AUTOSAR XML (schema 4-2-2)
package /STELLANTIS/EPT/ASWCs
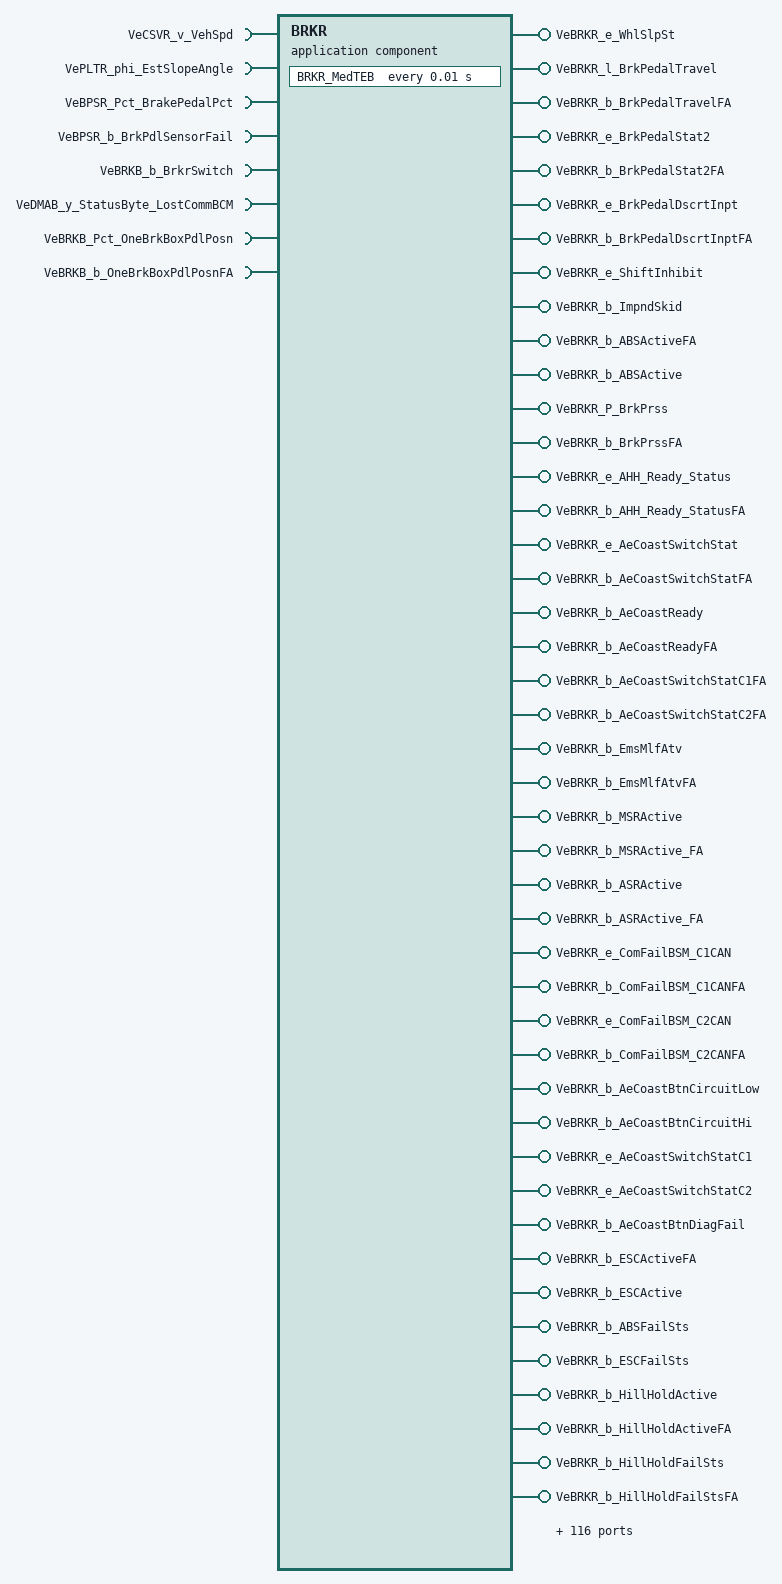
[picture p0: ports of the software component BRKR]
  application sw component type BRKR
    8 x require port, all with nonqueued-receiver-com-spec{data-element=Value, init-value=0}:
      VeCSVR_v_VehSpd: required-interface=VeCSVR_v_VehSpd
      VePLTR_phi_EstSlopeAngle: required-interface=VePLTR_phi_EstSlopeAngle
      VeBPSR_Pct_BrakePedalPct: required-interface=VeBPSR_Pct_BrakePedalPct
      VeBPSR_b_BrkPdlSensorFail: required-interface=VeBPSR_b_BrkPdlSensorFail
      VeBRKB_b_BrkrSwitch: required-interface=VeBRKB_b_BrkrSwitch
      VeDMAB_y_StatusByte_LostCommBCM: required-interface=VeDMAB_y_StatusByte_LostCommBCM
      VeBRKB_Pct_OneBrkBoxPdlPosn: required-interface=VeBRKB_Pct_OneBrkBoxPdlPosn
      VeBRKB_b_OneBrkBoxPdlPosnFA: required-interface=VeBRKB_b_OneBrkBoxPdlPosnFA
    160 x provide port:
      VeBRKR_e_WhlSlpSt: nonqueued-sender-com-spec{data-element=Value, init-value=CeBRKR_e_NoWhlSlpDetected}, provided-interface=VeBRKR_e_WhlSlpSt
      VeBRKR_l_BrkPedalTravel: nonqueued-sender-com-spec{data-element=Value, init-value=0}, provided-interface=VeBRKR_l_BrkPedalTravel
      VeBRKR_b_BrkPedalTravelFA: nonqueued-sender-com-spec{data-element=Value, init-value=0}, provided-interface=VeBRKR_b_BrkPedalTravelFA
      VeBRKR_e_BrkPedalStat2: nonqueued-sender-com-spec{data-element=Value, init-value=CeBRKR_e_BrkNotApplied}, provided-interface=VeBRKR_e_BrkPedalStat2
      VeBRKR_b_BrkPedalStat2FA: nonqueued-sender-com-spec{data-element=Value, init-value=0}, provided-interface=VeBRKR_b_BrkPedalStat2FA
      VeBRKR_e_BrkPedalDscrtInpt: nonqueued-sender-com-spec{data-element=Value, init-value=CeBRKR_e_BrkNotApplied}, provided-interface=VeBRKR_e_BrkPedalDscrtInpt
      VeBRKR_b_BrkPedalDscrtInptFA: nonqueued-sender-com-spec{data-element=Value, init-value=0}, provided-interface=VeBRKR_b_BrkPedalDscrtInptFA
      VeBRKR_e_ShiftInhibit: nonqueued-sender-com-spec{data-element=Value, init-value=CeBRKR_e_NoAction}, provided-interface=VeBRKR_e_ShiftInhibit
      VeBRKR_b_ImpndSkid: nonqueued-sender-com-spec{data-element=Value, init-value=0}, provided-interface=VeBRKR_b_ImpndSkid
      VeBRKR_b_ABSActiveFA: nonqueued-sender-com-spec{data-element=Value, init-value=0}, provided-interface=VeBRKR_b_ABSActiveFA
      VeBRKR_b_ABSActive: nonqueued-sender-com-spec{data-element=Value, init-value=0}, provided-interface=VeBRKR_b_ABSActive
      VeBRKR_P_BrkPrss: nonqueued-sender-com-spec{data-element=Value, init-value=0}, provided-interface=VeBRKR_P_BrkPrss
      VeBRKR_b_BrkPrssFA: nonqueued-sender-com-spec{data-element=Value, init-value=0}, provided-interface=VeBRKR_b_BrkPrssFA
      VeBRKR_e_AHH_Ready_Status: nonqueued-sender-com-spec{data-element=Value, init-value=CeBRKR_e_AHH_NotReady}, provided-interface=VeBRKR_e_AHH_Ready_Status
      VeBRKR_b_AHH_Ready_StatusFA: nonqueued-sender-com-spec{data-element=Value, init-value=0}, provided-interface=VeBRKR_b_AHH_Ready_StatusFA
      VeBRKR_e_AeCoastSwitchStat: nonqueued-sender-com-spec{data-element=Value, init-value=CeBRKR_e_Button_Unpressed}, provided-interface=VeBRKR_e_AeCoastSwitchStat
      VeBRKR_b_AeCoastSwitchStatFA: nonqueued-sender-com-spec{data-element=Value, init-value=0}, provided-interface=VeBRKR_b_AeCoastSwitchStatFA
      VeBRKR_b_AeCoastReady: nonqueued-sender-com-spec{data-element=Value, init-value=0}, provided-interface=VeBRKR_b_AeCoastReady
      VeBRKR_b_AeCoastReadyFA: nonqueued-sender-com-spec{data-element=Value, init-value=0}, provided-interface=VeBRKR_b_AeCoastReadyFA
      VeBRKR_b_AeCoastSwitchStatC1FA: nonqueued-sender-com-spec{data-element=Value, init-value=0}, provided-interface=VeBRKR_b_AeCoastSwitchStatC1FA
      VeBRKR_b_AeCoastSwitchStatC2FA: nonqueued-sender-com-spec{data-element=Value, init-value=0}, provided-interface=VeBRKR_b_AeCoastSwitchStatC2FA
      VeBRKR_b_EmsMlfAtv: nonqueued-sender-com-spec{data-element=Value, init-value=0}, provided-interface=VeBRKR_b_EmsMlfAtv
      VeBRKR_b_EmsMlfAtvFA: nonqueued-sender-com-spec{data-element=Value, init-value=0}, provided-interface=VeBRKR_b_EmsMlfAtvFA
      VeBRKR_b_MSRActive: nonqueued-sender-com-spec{data-element=Value, init-value=0}, provided-interface=VeBRKR_b_MSRActive
      VeBRKR_b_MSRActive_FA: nonqueued-sender-com-spec{data-element=Value, init-value=0}, provided-interface=VeBRKR_b_MSRActive_FA
      VeBRKR_b_ASRActive: nonqueued-sender-com-spec{data-element=Value, init-value=0}, provided-interface=VeBRKR_b_ASRActive
      VeBRKR_b_ASRActive_FA: nonqueued-sender-com-spec{data-element=Value, init-value=0}, provided-interface=VeBRKR_b_ASRActive_FA
      VeBRKR_e_ComFailBSM_C1CAN: nonqueued-sender-com-spec{data-element=Value, init-value=CeBRKR_e_NoFaultBSM_C1}, provided-interface=VeBRKR_e_ComFailBSM_C1CAN
      VeBRKR_b_ComFailBSM_C1CANFA: nonqueued-sender-com-spec{data-element=Value, init-value=0}, provided-interface=VeBRKR_b_ComFailBSM_C1CANFA
      VeBRKR_e_ComFailBSM_C2CAN: nonqueued-sender-com-spec{data-element=Value, init-value=CeBRKR_e_NoFaultBSM_C2}, provided-interface=VeBRKR_e_ComFailBSM_C2CAN
      VeBRKR_b_ComFailBSM_C2CANFA: nonqueued-sender-com-spec{data-element=Value, init-value=0}, provided-interface=VeBRKR_b_ComFailBSM_C2CANFA
      VeBRKR_b_AeCoastBtnCircuitLow: nonqueued-sender-com-spec{data-element=Value, init-value=0}, provided-interface=VeBRKR_b_AeCoastBtnCircuitLow
      VeBRKR_b_AeCoastBtnCircuitHi: nonqueued-sender-com-spec{data-element=Value, init-value=0}, provided-interface=VeBRKR_b_AeCoastBtnCircuitHi
      VeBRKR_e_AeCoastSwitchStatC1: nonqueued-sender-com-spec{data-element=Value, init-value=CeBRKR_e_Button_Unpressed}, provided-interface=VeBRKR_e_AeCoastSwitchStatC1
      VeBRKR_e_AeCoastSwitchStatC2: nonqueued-sender-com-spec{data-element=Value, init-value=CeBRKR_e_Button_Unpressed}, provided-interface=VeBRKR_e_AeCoastSwitchStatC2
      VeBRKR_b_AeCoastBtnDiagFail: nonqueued-sender-com-spec{data-element=Value, init-value=0}, provided-interface=VeBRKR_b_AeCoastBtnDiagFail
      VeBRKR_b_ESCActiveFA: nonqueued-sender-com-spec{data-element=Value, init-value=0}, provided-interface=VeBRKR_b_ESCActiveFA
      VeBRKR_b_ESCActive: nonqueued-sender-com-spec{data-element=Value, init-value=0}, provided-interface=VeBRKR_b_ESCActive
      VeBRKR_b_ABSFailSts: nonqueued-sender-com-spec{data-element=Value, init-value=0}, provided-interface=VeBRKR_b_ABSFailSts
      VeBRKR_b_ESCFailSts: nonqueued-sender-com-spec{data-element=Value, init-value=0}, provided-interface=VeBRKR_b_ESCFailSts
      VeBRKR_b_HillHoldActive: nonqueued-sender-com-spec{data-element=Value, init-value=0}, provided-interface=VeBRKR_b_HillHoldActive
      VeBRKR_b_HillHoldActiveFA: nonqueued-sender-com-spec{data-element=Value, init-value=0}, provided-interface=VeBRKR_b_HillHoldActiveFA
      VeBRKR_b_HillHoldFailSts: nonqueued-sender-com-spec{data-element=Value, init-value=0}, provided-interface=VeBRKR_b_HillHoldFailSts
      VeBRKR_b_HillHoldFailStsFA: nonqueued-sender-com-spec{data-element=Value, init-value=0}, provided-interface=VeBRKR_b_HillHoldFailStsFA
      VeBRKR_e_AeCoastSwitch: nonqueued-sender-com-spec{data-element=Value, init-value=CeBRKR_e_Button_Unpressed}, provided-interface=VeBRKR_e_AeCoastSwitch
      VeBRKR_b_AeCoastSwitchFA: nonqueued-sender-com-spec{data-element=Value, init-value=0}, provided-interface=VeBRKR_b_AeCoastSwitchFA
      VeBRKR_e_OPDHoldStatus: nonqueued-sender-com-spec{data-element=Value, init-value=CeBRKR_e_In_Active}, provided-interface=VeBRKR_e_OPDHoldStatus
      VeBRKR_b_OPDHoldStatusFA: nonqueued-sender-com-spec{data-element=Value, init-value=0}, provided-interface=VeBRKR_b_OPDHoldStatusFA
      VeBRKR_b_CMMIntervention: nonqueued-sender-com-spec{data-element=Value, init-value=0}, provided-interface=VeBRKR_b_CMMIntervention
      VeBRKR_b_FunctionSts: nonqueued-sender-com-spec{data-element=Value, init-value=0}, provided-interface=VeBRKR_b_FunctionSts
      VeBRKR_e_BrakeSrc: nonqueued-sender-com-spec{data-element=Value, init-value=CeBRKR_e_BrkPdlDscrtInpt}, provided-interface=VeBRKR_e_BrakeSrc
      VeBRKR_b_BrkMaxTrqIntrvntn: nonqueued-sender-com-spec{data-element=Value, init-value=0}, provided-interface=VeBRKR_b_BrkMaxTrqIntrvntn
      VeBRKR_b_BrkMinTrqIntrvntn: nonqueued-sender-com-spec{data-element=Value, init-value=0}, provided-interface=VeBRKR_b_BrkMinTrqIntrvntn
      VeBRKR_b_BrkMaxTrqIntrvntnFA: nonqueued-sender-com-spec{data-element=Value, init-value=0}, provided-interface=VeBRKR_b_BrkMaxTrqIntrvntnFA
      VeBRKR_b_BrkMinTrqIntrvntnFA: nonqueued-sender-com-spec{data-element=Value, init-value=0}, provided-interface=VeBRKR_b_BrkMinTrqIntrvntnFA
      VeBRKR_b_ReqSSC_IdlDst: nonqueued-sender-com-spec{data-element=Value, init-value=0}, provided-interface=VeBRKR_b_ReqSSC_IdlDst
      VeBRKR_b_ShortToGround: nonqueued-sender-com-spec{data-element=Value, init-value=0}, provided-interface=VeBRKR_b_ShortToGround
      VeBRKR_b_ShortToPower: nonqueued-sender-com-spec{data-element=Value, init-value=0}, provided-interface=VeBRKR_b_ShortToPower
      VeBRKR_b_ShortToOpen: nonqueued-sender-com-spec{data-element=Value, init-value=0}, provided-interface=VeBRKR_b_ShortToOpen
      VeBRKR_b_AeCoastBtnCircuitLowC1: nonqueued-sender-com-spec{data-element=Value, init-value=0}, provided-interface=VeBRKR_b_AeCoastBtnCircuitLowC1
      VeBRKR_b_AeCoastBtnCircuitLowC2: nonqueued-sender-com-spec{data-element=Value, init-value=0}, provided-interface=VeBRKR_b_AeCoastBtnCircuitLowC2
      VeBRKR_b_AeCoastBtnCircuitHiC1: nonqueued-sender-com-spec{data-element=Value, init-value=0}, provided-interface=VeBRKR_b_AeCoastBtnCircuitHiC1
      VeBRKR_b_AeCoastBtnCircuitHiC2: nonqueued-sender-com-spec{data-element=Value, init-value=0}, provided-interface=VeBRKR_b_AeCoastBtnCircuitHiC2
      VeBRKR_e_ExtBrkReqOff: nonqueued-sender-com-spec{data-element=Value, init-value=CeBRKR_e_NoReq}, provided-interface=VeBRKR_e_ExtBrkReqOff
      VeBRKR_b_ExtBrkReqOffFA: nonqueued-sender-com-spec{data-element=Value, init-value=0}, provided-interface=VeBRKR_b_ExtBrkReqOffFA
      VeBRKR_b_BrkPdlFlt: nonqueued-sender-com-spec{data-element=Value, init-value=0}, provided-interface=VeBRKR_b_BrkPdlFlt
      VeBRKR_b_BrkPdlFltFA: nonqueued-sender-com-spec{data-element=Value, init-value=0}, provided-interface=VeBRKR_b_BrkPdlFltFA
      VeBRKR_e_ExtTcsReqOff: nonqueued-sender-com-spec{data-element=Value, init-value=CeBRKR_e_NoReq}, provided-interface=VeBRKR_e_ExtTcsReqOff
      VeBRKR_Pct_BrkTravelSts: nonqueued-sender-com-spec{data-element=Value, init-value=0}, provided-interface=VeBRKR_Pct_BrkTravelSts
      VeBRKR_b_BrkTravelStsFA: nonqueued-sender-com-spec{data-element=Value, init-value=0}, provided-interface=VeBRKR_b_BrkTravelStsFA
      VeBRKR_b_ESCFailStsFA: nonqueued-sender-com-spec{data-element=Value, init-value=0}, provided-interface=VeBRKR_b_ESCFailStsFA
      VeBRKR_pbar_BrakePedalPressure: nonqueued-sender-com-spec{data-element=Value, init-value=0}, provided-interface=VeBRKR_pbar_BrakePedalPressure
      VeBRKR_b_ESCIntervention: nonqueued-sender-com-spec{data-element=Value, init-value=0}, provided-interface=VeBRKR_b_ESCIntervention
      VeBRKR_e_FaultSts_RgnCntrlSwCktHi: nonqueued-sender-com-spec{data-element=Value, init-value=CeDFIB_e_Init}, provided-interface=VeBRKR_e_FaultSts_RgnCntrlSwCktHi
      VeBRKR_e_FaultSts_RgnCntrlSwCktLo: nonqueued-sender-com-spec{data-element=Value, init-value=CeDFIB_e_Init}, provided-interface=VeBRKR_e_FaultSts_RgnCntrlSwCktLo
      VeBRKR_e_FaultSts_RgnCntrlSwCkt: nonqueued-sender-com-spec{data-element=Value, init-value=CeDFIB_e_Init}, provided-interface=VeBRKR_e_FaultSts_RgnCntrlSwCkt
      VeBRKR_b_VehicleStandStillSts: nonqueued-sender-com-spec{data-element=Value, init-value=0}, provided-interface=VeBRKR_b_VehicleStandStillSts
      VeBRKR_b_VehicleStandStillStsFA: nonqueued-sender-com-spec{data-element=Value, init-value=0}, provided-interface=VeBRKR_b_VehicleStandStillStsFA
      VeBRKR_e_Not_OK_To_Race: nonqueued-sender-com-spec{data-element=Value, init-value=CeBRKR_e_OK}, provided-interface=VeBRKR_e_Not_OK_To_Race
      VeBRKR_b_Not_OK_To_RaceFA: nonqueued-sender-com-spec{data-element=Value, init-value=0}, provided-interface=VeBRKR_b_Not_OK_To_RaceFA
      VeBRKR_b_BrkTempSts: nonqueued-sender-com-spec{data-element=Value, init-value=0}, provided-interface=VeBRKR_b_BrkTempSts
      VeBRKR_b_BrkTempStsFA: nonqueued-sender-com-spec{data-element=Value, init-value=0}, provided-interface=VeBRKR_b_BrkTempStsFA
      VeBRKR_b_OneBrkBoxPdlPosnFA: nonqueued-sender-com-spec{data-element=Value, init-value=0}, provided-interface=VeBRKR_b_OneBrkBoxPdlPosnFA
      VeBRKR_Pct_OneBrkBoxPdlPosn: nonqueued-sender-com-spec{data-element=Value, init-value=0}, provided-interface=VeBRKR_Pct_OneBrkBoxPdlPosn
      FsftBRKR_P_BrkPrss: server-com-spec=FsftBRKR_P_BrkPrss, provided-interface=FsftBRKR_P_BrkPrss
      FsftBRKR_b_ABSActive: server-com-spec=FsftBRKR_b_ABSActive, provided-interface=FsftBRKR_b_ABSActive
      FsftBRKR_b_ASRActive: server-com-spec=FsftBRKR_b_ASRActive, provided-interface=FsftBRKR_b_ASRActive
      FsftBRKR_b_AeCoastReady: server-com-spec=FsftBRKR_b_AeCoastReady, provided-interface=FsftBRKR_b_AeCoastReady
      FsftBRKR_b_BrkMaxTrqIntrvntn: server-com-spec=FsftBRKR_b_BrkMaxTrqIntrvntn, provided-interface=FsftBRKR_b_BrkMaxTrqIntrvntn
      FsftBRKR_b_BrkMinTrqIntrvntn: server-com-spec=FsftBRKR_b_BrkMinTrqIntrvntn, provided-interface=FsftBRKR_b_BrkMinTrqIntrvntn
      FsftBRKR_b_BrkPdlFlt: server-com-spec=FsftBRKR_b_BrkPdlFlt, provided-interface=FsftBRKR_b_BrkPdlFlt
      FsftBRKR_b_BrkPedalDscrtInpt: server-com-spec=FsftBRKR_b_BrkPedalDscrtInpt, provided-interface=FsftBRKR_b_BrkPedalDscrtInpt
      FsftBRKR_b_BrkPedalStat2: server-com-spec=FsftBRKR_b_BrkPedalStat2, provided-interface=FsftBRKR_b_BrkPedalStat2
      FsftBRKR_b_BrkPedalStat2_C2CAN: server-com-spec=FsftBRKR_b_BrkPedalStat2_C2CAN, provided-interface=FsftBRKR_b_BrkPedalStat2_C2CAN
      FsftBRKR_b_BrkPedalSts: server-com-spec=FsftBRKR_b_BrkPedalSts, provided-interface=FsftBRKR_b_BrkPedalSts
      FsftBRKR_b_BrkTmpSts: server-com-spec=FsftBRKR_b_BrkTmpSts, provided-interface=FsftBRKR_b_BrkTmpSts
      FsftBRKR_b_BrkTravelSts: server-com-spec=FsftBRKR_b_BrkTravelSts, provided-interface=FsftBRKR_b_BrkTravelSts
      FsftBRKR_b_BrkTravelSts_C2CAN: server-com-spec=FsftBRKR_b_BrkTravelSts_C2CAN, provided-interface=FsftBRKR_b_BrkTravelSts_C2CAN
      FsftBRKR_b_ESCActive: server-com-spec=FsftBRKR_b_ESCActive, provided-interface=FsftBRKR_b_ESCActive
      FsftBRKR_b_ESCFailSts: server-com-spec=FsftBRKR_b_ESCFailSts, provided-interface=FsftBRKR_b_ESCFailSts
      FsftBRKR_b_ESCIntervention: server-com-spec=FsftBRKR_b_ESCIntervention, provided-interface=FsftBRKR_b_ESCIntervention
      FsftBRKR_b_EmsMlfAtv: server-com-spec=FsftBRKR_b_EmsMlfAtv, provided-interface=FsftBRKR_b_EmsMlfAtv
      FsftBRKR_b_HillHoldActive: server-com-spec=FsftBRKR_b_HillHoldActive, provided-interface=FsftBRKR_b_HillHoldActive
      FsftBRKR_b_HillHoldFailSts: server-com-spec=FsftBRKR_b_HillHoldFailSts, provided-interface=FsftBRKR_b_HillHoldFailSts
      FsftBRKR_b_MSRActive: server-com-spec=FsftBRKR_b_MSRActive, provided-interface=FsftBRKR_b_MSRActive
      FsftBRKR_b_VehicleStandStillSts: server-com-spec=FsftBRKR_b_VehicleStandStillSts, provided-interface=FsftBRKR_b_VehicleStandStillSts
      FsftBRKR_e_AHH_Ready_Status: server-com-spec=FsftBRKR_e_AHH_Ready_Status, provided-interface=FsftBRKR_e_AHH_Ready_Status
      FsftBRKR_e_AeCoastSwitch: server-com-spec=FsftBRKR_e_AeCoastSwitch, provided-interface=FsftBRKR_e_AeCoastSwitch
      FsftBRKR_e_AeCoastSwitchStat: server-com-spec=FsftBRKR_e_AeCoastSwitchStat, provided-interface=FsftBRKR_e_AeCoastSwitchStat
      FsftBRKR_e_AeCoastSwitchStatC1: server-com-spec=FsftBRKR_e_AeCoastSwitchStatC1, provided-interface=FsftBRKR_e_AeCoastSwitchStatC1
      FsftBRKR_e_AeCoastSwitchStatC2: server-com-spec=FsftBRKR_e_AeCoastSwitchStatC2, provided-interface=FsftBRKR_e_AeCoastSwitchStatC2
      FsftBRKR_e_BSMComFailDflt_C1CAN: server-com-spec=FsftBRKR_e_BSMComFailDflt_C1CAN, provided-interface=FsftBRKR_e_BSMComFailDflt_C1CAN
      FsftBRKR_e_BSMComFailDflt_C2CAN: server-com-spec=FsftBRKR_e_BSMComFailDflt_C2CAN, provided-interface=FsftBRKR_e_BSMComFailDflt_C2CAN
      FsftBRKR_e_ExtBrkReqOff: server-com-spec=FsftBRKR_e_ExtBrkReqOff, provided-interface=FsftBRKR_e_ExtBrkReqOff
      FsftBRKR_e_Not_OK_To_Race: server-com-spec=FsftBRKR_e_Not_OK_To_Race, provided-interface=FsftBRKR_e_Not_OK_To_Race
      FsftBRKR_e_OPDHoldStatus: server-com-spec=FsftBRKR_e_OPDHoldStatus, provided-interface=FsftBRKR_e_OPDHoldStatus
      FsftBRKR_pbar_BrakePedalPressure: server-com-spec=FsftBRKR_pbar_BrakePedalPressure, provided-interface=FsftBRKR_pbar_BrakePedalPressure
      PokeBRKR_P_BrkPrss: server-com-spec{operation=PokeBRKR_P_BrkPrss, queue-length=1}, provided-interface=PokeBRKR_P_BrkPrss
      PokeBRKR_Pct_BrkTravelSt_C2CAN: server-com-spec{operation=PokeBRKR_Pct_BrkTravelSt_C2CAN, queue-length=1}, provided-interface=PokeBRKR_Pct_BrkTravelSt_C2CAN
      PokeBRKR_Pct_BrkTravelSts: server-com-spec{operation=PokeBRKR_Pct_BrkTravelSts, queue-length=1}, provided-interface=PokeBRKR_Pct_BrkTravelSts
      PokeBRKR_U_Brake_NO: server-com-spec{operation=PokeBRKR_U_Brake_NO, queue-length=1}, provided-interface=PokeBRKR_U_Brake_NO
      PokeBRKR_b_ABSActive: server-com-spec{operation=PokeBRKR_b_ABSActive, queue-length=1}, provided-interface=PokeBRKR_b_ABSActive
      PokeBRKR_b_ABSFailSts: server-com-spec{operation=PokeBRKR_b_ABSFailSts, queue-length=1}, provided-interface=PokeBRKR_b_ABSFailSts
      PokeBRKR_b_ASRActive: server-com-spec{operation=PokeBRKR_b_ASRActive, queue-length=1}, provided-interface=PokeBRKR_b_ASRActive
      PokeBRKR_b_AeCoastReady: server-com-spec{operation=PokeBRKR_b_AeCoastReady, queue-length=1}, provided-interface=PokeBRKR_b_AeCoastReady
      PokeBRKR_b_BrkMaxTrqIntrvntn: server-com-spec{operation=PokeBRKR_b_BrkMaxTrqIntrvntn, queue-length=1}, provided-interface=PokeBRKR_b_BrkMaxTrqIntrvntn
      PokeBRKR_b_BrkMinTrqIntrvntn: server-com-spec{operation=PokeBRKR_b_BrkMinTrqIntrvntn, queue-length=1}, provided-interface=PokeBRKR_b_BrkMinTrqIntrvntn
      PokeBRKR_b_BrkPdlFlt: server-com-spec{operation=PokeBRKR_b_BrkPdlFlt, queue-length=1}, provided-interface=PokeBRKR_b_BrkPdlFlt
      PokeBRKR_b_BrkTmpSts: server-com-spec{operation=PokeBRKR_b_BrkTmpSts, queue-length=1}, provided-interface=PokeBRKR_b_BrkTmpSts
      PokeBRKR_b_CMMIntervention: server-com-spec{operation=PokeBRKR_b_CMMIntervention, queue-length=1}, provided-interface=PokeBRKR_b_CMMIntervention
      PokeBRKR_b_ESCActive: server-com-spec{operation=PokeBRKR_b_ESCActive, queue-length=1}, provided-interface=PokeBRKR_b_ESCActive
      PokeBRKR_b_ESCFailSts: server-com-spec{operation=PokeBRKR_b_ESCFailSts, queue-length=1}, provided-interface=PokeBRKR_b_ESCFailSts
      PokeBRKR_b_ESCIntervention: server-com-spec{operation=PokeBRKR_b_ESCIntervention, queue-length=1}, provided-interface=PokeBRKR_b_ESCIntervention
      PokeBRKR_b_EmsMlfAtv: server-com-spec{operation=PokeBRKR_b_EmsMlfAtv, queue-length=1}, provided-interface=PokeBRKR_b_EmsMlfAtv
      PokeBRKR_b_FunctionSts: server-com-spec{operation=PokeBRKR_b_FunctionSts, queue-length=1}, provided-interface=PokeBRKR_b_FunctionSts
      PokeBRKR_b_HillHoldActive: server-com-spec{operation=PokeBRKR_b_HillHoldActive, queue-length=1}, provided-interface=PokeBRKR_b_HillHoldActive
      PokeBRKR_b_HillHoldFailSts: server-com-spec{operation=PokeBRKR_b_HillHoldFailSts, queue-length=1}, provided-interface=PokeBRKR_b_HillHoldFailSts
      PokeBRKR_b_ImpndSkid: server-com-spec{operation=PokeBRKR_b_ImpndSkid, queue-length=1}, provided-interface=PokeBRKR_b_ImpndSkid
      PokeBRKR_b_MSRActive: server-com-spec{operation=PokeBRKR_b_MSRActive, queue-length=1}, provided-interface=PokeBRKR_b_MSRActive
      PokeBRKR_b_VehicleStandStillSts: server-com-spec{operation=PokeBRKR_b_VehicleStandStillSts, queue-length=1}, provided-interface=PokeBRKR_b_VehicleStandStillSts
      PokeBRKR_e_AHH_Ready_Status: server-com-spec{operation=PokeBRKR_e_AHH_Ready_Status, queue-length=1}, provided-interface=PokeBRKR_e_AHH_Ready_Status
      PokeBRKR_e_AeCoastSwitch: server-com-spec{operation=PokeBRKR_e_AeCoastSwitch, queue-length=1}, provided-interface=PokeBRKR_e_AeCoastSwitch
      PokeBRKR_e_AeCoastSwitchStat: server-com-spec{operation=PokeBRKR_e_AeCoastSwitchStat, queue-length=1}, provided-interface=PokeBRKR_e_AeCoastSwitchStat
      PokeBRKR_e_AeCoastSwitchStatC1: server-com-spec{operation=PokeBRKR_e_AeCoastSwitchStatC1, queue-length=1}, provided-interface=PokeBRKR_e_AeCoastSwitchStatC1
      PokeBRKR_e_AeCoastSwitchStatC2: server-com-spec{operation=PokeBRKR_e_AeCoastSwitchStatC2, queue-length=1}, provided-interface=PokeBRKR_e_AeCoastSwitchStatC2
      PokeBRKR_e_BSMComFail_C1CAN: server-com-spec{operation=PokeBRKR_e_BSMComFail_C1CAN, queue-length=1}, provided-interface=PokeBRKR_e_BSMComFail_C1CAN
      PokeBRKR_e_BSMComFail_C2CAN: server-com-spec{operation=PokeBRKR_e_BSMComFail_C2CAN, queue-length=1}, provided-interface=PokeBRKR_e_BSMComFail_C2CAN
      PokeBRKR_e_BrkPedalDscrtInpt: server-com-spec{operation=PokeBRKR_e_BrkPedalDscrtInpt, queue-length=1}, provided-interface=PokeBRKR_e_BrkPedalDscrtInpt
      PokeBRKR_e_BrkPedalStat2: server-com-spec{operation=PokeBRKR_e_BrkPedalStat2, queue-length=1}, provided-interface=PokeBRKR_e_BrkPedalStat2
      PokeBRKR_e_BrkPedalStat2_C2CAN: server-com-spec{operation=PokeBRKR_e_BrkPedalStat2_C2CAN, queue-length=1}, provided-interface=PokeBRKR_e_BrkPedalStat2_C2CAN
      PokeBRKR_e_BrkPedalSts: server-com-spec{operation=PokeBRKR_e_BrkPedalSts, queue-length=1}, provided-interface=PokeBRKR_e_BrkPedalSts
      PokeBRKR_e_ExtBrkReqOff: server-com-spec{operation=PokeBRKR_e_ExtBrkReqOff, queue-length=1}, provided-interface=PokeBRKR_e_ExtBrkReqOff
      PokeBRKR_e_ExtTcsReqOff: server-com-spec{operation=PokeBRKR_e_ExtTcsReqOff, queue-length=1}, provided-interface=PokeBRKR_e_ExtTcsReqOff
      PokeBRKR_e_Not_OK_To_Race: server-com-spec{operation=PokeBRKR_e_Not_OK_To_Race, queue-length=1}, provided-interface=PokeBRKR_e_Not_OK_To_Race
      PokeBRKR_e_OPDHoldStatus: server-com-spec{operation=PokeBRKR_e_OPDHoldStatus, queue-length=1}, provided-interface=PokeBRKR_e_OPDHoldStatus
      PokeBRKR_e_ReqSSC_IdlDst: server-com-spec{operation=PokeBRKR_e_ReqSSC_IdlDst, queue-length=1}, provided-interface=PokeBRKR_e_ReqSSC_IdlDst
      PokeBRKR_e_ShiftInhibit: server-com-spec{operation=PokeBRKR_e_ShiftInhibit, queue-length=1}, provided-interface=PokeBRKR_e_ShiftInhibit
      PokeBRKR_e_WhlSlpSt: server-com-spec{operation=PokeBRKR_e_WhlSlpSt, queue-length=1}, provided-interface=PokeBRKR_e_WhlSlpSt
      PokeBRKR_l_BrkPedalTravel: server-com-spec{operation=PokeBRKR_l_BrkPedalTravel, queue-length=1}, provided-interface=PokeBRKR_l_BrkPedalTravel
      PokeBRKR_pbar_BrakePedalPressure: server-com-spec{operation=PokeBRKR_pbar_BrakePedalPressure, queue-length=1}, provided-interface=PokeBRKR_pbar_BrakePedalPressure
    behavior IB_BRKR: data-type-mapping=msADTtoIDTMapping, handle-termination-and-restart=NO-SUPPORT, included-data-type-set=data-type=TeBRKR_e_DiagStatus
      timing event Event_MedTEB: start-on-event=BRKR_MedTEB, period=0.01
      76 x operation invoked event:
        Event_FsftBRKR_P_BrkPrss: start-on-event=FsftBRKR_P_BrkPrss, operation=FsftBRKR_P_BrkPrss.FsftBRKR_P_BrkPrss
        Event_FsftBRKR_b_ABSActive: start-on-event=FsftBRKR_b_ABSActive, operation=FsftBRKR_b_ABSActive.FsftBRKR_b_ABSActive
        Event_FsftBRKR_b_ASRActive: start-on-event=FsftBRKR_b_ASRActive, operation=FsftBRKR_b_ASRActive.FsftBRKR_b_ASRActive
        Event_FsftBRKR_b_AeCoastReady: start-on-event=FsftBRKR_b_AeCoastReady, operation=FsftBRKR_b_AeCoastReady.FsftBRKR_b_AeCoastReady
        Event_FsftBRKR_b_BrkMaxTrqIntrvntn: start-on-event=FsftBRKR_b_BrkMaxTrqIntrvntn, operation=FsftBRKR_b_BrkMaxTrqIntrvntn.FsftBRKR_b_BrkMaxTrqIntrvntn
        Event_FsftBRKR_b_BrkMinTrqIntrvntn: start-on-event=FsftBRKR_b_BrkMinTrqIntrvntn, operation=FsftBRKR_b_BrkMinTrqIntrvntn.FsftBRKR_b_BrkMinTrqIntrvntn
        Event_FsftBRKR_b_BrkPdlFlt: start-on-event=FsftBRKR_b_BrkPdlFlt, operation=FsftBRKR_b_BrkPdlFlt.FsftBRKR_b_BrkPdlFlt
        Event_FsftBRKR_b_BrkPedalDscrtInpt: start-on-event=FsftBRKR_b_BrkPedalDscrtInpt, operation=FsftBRKR_b_BrkPedalDscrtInpt.FsftBRKR_b_BrkPedalDscrtInpt
        Event_FsftBRKR_b_BrkPedalStat2: start-on-event=FsftBRKR_b_BrkPedalStat2, operation=FsftBRKR_b_BrkPedalStat2.FsftBRKR_b_BrkPedalStat2
        Event_FsftBRKR_b_BrkPedalStat2_C2CAN: start-on-event=FsftBRKR_b_BrkPedalStat2_C2CAN, operation=FsftBRKR_b_BrkPedalStat2_C2CAN.FsftBRKR_b_BrkPedalStat2_C2CAN
        Event_FsftBRKR_b_BrkPedalSts: start-on-event=FsftBRKR_b_BrkPedalSts, operation=FsftBRKR_b_BrkPedalSts.FsftBRKR_b_BrkPedalSts
        Event_FsftBRKR_b_BrkTmpSts: start-on-event=FsftBRKR_b_BrkTmpSts, operation=FsftBRKR_b_BrkTmpSts.FsftBRKR_b_BrkTmpSts
        Event_FsftBRKR_b_BrkTravelSts: start-on-event=FsftBRKR_b_BrkTravelSts, operation=FsftBRKR_b_BrkTravelSts.FsftBRKR_b_BrkTravelSts
        Event_FsftBRKR_b_BrkTravelSts_C2CAN: start-on-event=FsftBRKR_b_BrkTravelSts_C2CAN, operation=FsftBRKR_b_BrkTravelSts_C2CAN.FsftBRKR_b_BrkTravelSts_C2CAN
        Event_FsftBRKR_b_ESCActive: start-on-event=FsftBRKR_b_ESCActive, operation=FsftBRKR_b_ESCActive.FsftBRKR_b_ESCActive
        Event_FsftBRKR_b_ESCFailSts: start-on-event=FsftBRKR_b_ESCFailSts, operation=FsftBRKR_b_ESCFailSts.FsftBRKR_b_ESCFailSts
        Event_FsftBRKR_b_ESCIntervention: start-on-event=FsftBRKR_b_ESCIntervention, operation=FsftBRKR_b_ESCIntervention.FsftBRKR_b_ESCIntervention
        Event_FsftBRKR_b_EmsMlfAtv: start-on-event=FsftBRKR_b_EmsMlfAtv, operation=FsftBRKR_b_EmsMlfAtv.FsftBRKR_b_EmsMlfAtv
        Event_FsftBRKR_b_HillHoldActive: start-on-event=FsftBRKR_b_HillHoldActive, operation=FsftBRKR_b_HillHoldActive.FsftBRKR_b_HillHoldActive
        Event_FsftBRKR_b_HillHoldFailSts: start-on-event=FsftBRKR_b_HillHoldFailSts, operation=FsftBRKR_b_HillHoldFailSts.FsftBRKR_b_HillHoldFailSts
        Event_FsftBRKR_b_MSRActive: start-on-event=FsftBRKR_b_MSRActive, operation=FsftBRKR_b_MSRActive.FsftBRKR_b_MSRActive
        Event_FsftBRKR_b_VehicleStandStillSts: start-on-event=FsftBRKR_b_VehicleStandStillSts, operation=FsftBRKR_b_VehicleStandStillSts.FsftBRKR_b_VehicleStandStillSts
        Event_FsftBRKR_e_AHH_Ready_Status: start-on-event=FsftBRKR_e_AHH_Ready_Status, operation=FsftBRKR_e_AHH_Ready_Status.FsftBRKR_e_AHH_Ready_Status
        Event_FsftBRKR_e_AeCoastSwitch: start-on-event=FsftBRKR_e_AeCoastSwitch, operation=FsftBRKR_e_AeCoastSwitch.FsftBRKR_e_AeCoastSwitch
        Event_FsftBRKR_e_AeCoastSwitchStat: start-on-event=FsftBRKR_e_AeCoastSwitchStat, operation=FsftBRKR_e_AeCoastSwitchStat.FsftBRKR_e_AeCoastSwitchStat
        Event_FsftBRKR_e_AeCoastSwitchStatC1: start-on-event=FsftBRKR_e_AeCoastSwitchStatC1, operation=FsftBRKR_e_AeCoastSwitchStatC1.FsftBRKR_e_AeCoastSwitchStatC1
        Event_FsftBRKR_e_AeCoastSwitchStatC2: start-on-event=FsftBRKR_e_AeCoastSwitchStatC2, operation=FsftBRKR_e_AeCoastSwitchStatC2.FsftBRKR_e_AeCoastSwitchStatC2
        Event_FsftBRKR_e_BSMComFailDflt_C1CAN: start-on-event=FsftBRKR_e_BSMComFailDflt_C1CAN, operation=FsftBRKR_e_BSMComFailDflt_C1CAN.FsftBRKR_e_BSMComFailDflt_C1CAN
        Event_FsftBRKR_e_BSMComFailDflt_C2CAN: start-on-event=FsftBRKR_e_BSMComFailDflt_C2CAN, operation=FsftBRKR_e_BSMComFailDflt_C2CAN.FsftBRKR_e_BSMComFailDflt_C2CAN
        Event_FsftBRKR_e_ExtBrkReqOff: start-on-event=FsftBRKR_e_ExtBrkReqOff, operation=FsftBRKR_e_ExtBrkReqOff.FsftBRKR_e_ExtBrkReqOff
        Event_FsftBRKR_e_Not_OK_To_Race: start-on-event=FsftBRKR_e_Not_OK_To_Race, operation=FsftBRKR_e_Not_OK_To_Race.FsftBRKR_e_Not_OK_To_Race
        Event_FsftBRKR_e_OPDHoldStatus: start-on-event=FsftBRKR_e_OPDHoldStatus, operation=FsftBRKR_e_OPDHoldStatus.FsftBRKR_e_OPDHoldStatus
        Event_FsftBRKR_pbar_BrakePedalPressure: start-on-event=FsftBRKR_pbar_BrakePedalPressure, operation=FsftBRKR_pbar_BrakePedalPressure.FsftBRKR_pbar_BrakePedalPressure
        Event_PokeBRKR_P_BrkPrss: start-on-event=PokeBRKR_P_BrkPrss, operation=PokeBRKR_P_BrkPrss.PokeBRKR_P_BrkPrss
        Event_PokeBRKR_Pct_BrkTravelSt_C2CAN: start-on-event=PokeBRKR_Pct_BrkTravelSt_C2CAN, operation=PokeBRKR_Pct_BrkTravelSt_C2CAN.PokeBRKR_Pct_BrkTravelSt_C2CAN
        Event_PokeBRKR_Pct_BrkTravelSts: start-on-event=PokeBRKR_Pct_BrkTravelSts, operation=PokeBRKR_Pct_BrkTravelSts.PokeBRKR_Pct_BrkTravelSts
        Event_PokeBRKR_U_Brake_NO: start-on-event=PokeBRKR_U_Brake_NO, operation=PokeBRKR_U_Brake_NO.PokeBRKR_U_Brake_NO
        Event_PokeBRKR_b_ABSActive: start-on-event=PokeBRKR_b_ABSActive, operation=PokeBRKR_b_ABSActive.PokeBRKR_b_ABSActive
        Event_PokeBRKR_b_ABSFailSts: start-on-event=PokeBRKR_b_ABSFailSts, operation=PokeBRKR_b_ABSFailSts.PokeBRKR_b_ABSFailSts
        Event_PokeBRKR_b_ASRActive: start-on-event=PokeBRKR_b_ASRActive, operation=PokeBRKR_b_ASRActive.PokeBRKR_b_ASRActive
        Event_PokeBRKR_b_AeCoastReady: start-on-event=PokeBRKR_b_AeCoastReady, operation=PokeBRKR_b_AeCoastReady.PokeBRKR_b_AeCoastReady
        Event_PokeBRKR_b_BrkMaxTrqIntrvntn: start-on-event=PokeBRKR_b_BrkMaxTrqIntrvntn, operation=PokeBRKR_b_BrkMaxTrqIntrvntn.PokeBRKR_b_BrkMaxTrqIntrvntn
        Event_PokeBRKR_b_BrkMinTrqIntrvntn: start-on-event=PokeBRKR_b_BrkMinTrqIntrvntn, operation=PokeBRKR_b_BrkMinTrqIntrvntn.PokeBRKR_b_BrkMinTrqIntrvntn
        Event_PokeBRKR_b_BrkPdlFlt: start-on-event=PokeBRKR_b_BrkPdlFlt, operation=PokeBRKR_b_BrkPdlFlt.PokeBRKR_b_BrkPdlFlt
        Event_PokeBRKR_b_BrkTmpSts: start-on-event=PokeBRKR_b_BrkTmpSts, operation=PokeBRKR_b_BrkTmpSts.PokeBRKR_b_BrkTmpSts
        Event_PokeBRKR_b_CMMIntervention: start-on-event=PokeBRKR_b_CMMIntervention, operation=PokeBRKR_b_CMMIntervention.PokeBRKR_b_CMMIntervention
        Event_PokeBRKR_b_ESCActive: start-on-event=PokeBRKR_b_ESCActive, operation=PokeBRKR_b_ESCActive.PokeBRKR_b_ESCActive
        Event_PokeBRKR_b_ESCFailSts: start-on-event=PokeBRKR_b_ESCFailSts, operation=PokeBRKR_b_ESCFailSts.PokeBRKR_b_ESCFailSts
        Event_PokeBRKR_b_ESCIntervention: start-on-event=PokeBRKR_b_ESCIntervention, operation=PokeBRKR_b_ESCIntervention.PokeBRKR_b_ESCIntervention
        Event_PokeBRKR_b_EmsMlfAtv: start-on-event=PokeBRKR_b_EmsMlfAtv, operation=PokeBRKR_b_EmsMlfAtv.PokeBRKR_b_EmsMlfAtv
        Event_PokeBRKR_b_FunctionSts: start-on-event=PokeBRKR_b_FunctionSts, operation=PokeBRKR_b_FunctionSts.PokeBRKR_b_FunctionSts
        Event_PokeBRKR_b_HillHoldActive: start-on-event=PokeBRKR_b_HillHoldActive, operation=PokeBRKR_b_HillHoldActive.PokeBRKR_b_HillHoldActive
        Event_PokeBRKR_b_HillHoldFailSts: start-on-event=PokeBRKR_b_HillHoldFailSts, operation=PokeBRKR_b_HillHoldFailSts.PokeBRKR_b_HillHoldFailSts
        Event_PokeBRKR_b_ImpndSkid: start-on-event=PokeBRKR_b_ImpndSkid, operation=PokeBRKR_b_ImpndSkid.PokeBRKR_b_ImpndSkid
        Event_PokeBRKR_b_MSRActive: start-on-event=PokeBRKR_b_MSRActive, operation=PokeBRKR_b_MSRActive.PokeBRKR_b_MSRActive
        Event_PokeBRKR_b_VehicleStandStillSts: start-on-event=PokeBRKR_b_VehicleStandStillSts, operation=PokeBRKR_b_VehicleStandStillSts.PokeBRKR_b_VehicleStandStillSts
        Event_PokeBRKR_e_AHH_Ready_Status: start-on-event=PokeBRKR_e_AHH_Ready_Status, operation=PokeBRKR_e_AHH_Ready_Status.PokeBRKR_e_AHH_Ready_Status
        Event_PokeBRKR_e_AeCoastSwitch: start-on-event=PokeBRKR_e_AeCoastSwitch, operation=PokeBRKR_e_AeCoastSwitch.PokeBRKR_e_AeCoastSwitch
        Event_PokeBRKR_e_AeCoastSwitchStat: start-on-event=PokeBRKR_e_AeCoastSwitchStat, operation=PokeBRKR_e_AeCoastSwitchStat.PokeBRKR_e_AeCoastSwitchStat
        Event_PokeBRKR_e_AeCoastSwitchStatC1: start-on-event=PokeBRKR_e_AeCoastSwitchStatC1, operation=PokeBRKR_e_AeCoastSwitchStatC1.PokeBRKR_e_AeCoastSwitchStatC1
        Event_PokeBRKR_e_AeCoastSwitchStatC2: start-on-event=PokeBRKR_e_AeCoastSwitchStatC2, operation=PokeBRKR_e_AeCoastSwitchStatC2.PokeBRKR_e_AeCoastSwitchStatC2
        Event_PokeBRKR_e_BSMComFail_C1CAN: start-on-event=PokeBRKR_e_BSMComFail_C1CAN, operation=PokeBRKR_e_BSMComFail_C1CAN.PokeBRKR_e_BSMComFail_C1CAN
        Event_PokeBRKR_e_BSMComFail_C2CAN: start-on-event=PokeBRKR_e_BSMComFail_C2CAN, operation=PokeBRKR_e_BSMComFail_C2CAN.PokeBRKR_e_BSMComFail_C2CAN
        Event_PokeBRKR_e_BrkPedalDscrtInpt: start-on-event=PokeBRKR_e_BrkPedalDscrtInpt, operation=PokeBRKR_e_BrkPedalDscrtInpt.PokeBRKR_e_BrkPedalDscrtInpt
        Event_PokeBRKR_e_BrkPedalStat2: start-on-event=PokeBRKR_e_BrkPedalStat2, operation=PokeBRKR_e_BrkPedalStat2.PokeBRKR_e_BrkPedalStat2
        Event_PokeBRKR_e_BrkPedalStat2_C2CAN: start-on-event=PokeBRKR_e_BrkPedalStat2_C2CAN, operation=PokeBRKR_e_BrkPedalStat2_C2CAN.PokeBRKR_e_BrkPedalStat2_C2CAN
        Event_PokeBRKR_e_BrkPedalSts: start-on-event=PokeBRKR_e_BrkPedalSts, operation=PokeBRKR_e_BrkPedalSts.PokeBRKR_e_BrkPedalSts
        Event_PokeBRKR_e_ExtBrkReqOff: start-on-event=PokeBRKR_e_ExtBrkReqOff, operation=PokeBRKR_e_ExtBrkReqOff.PokeBRKR_e_ExtBrkReqOff
        Event_PokeBRKR_e_ExtTcsReqOff: start-on-event=PokeBRKR_e_ExtTcsReqOff, operation=PokeBRKR_e_ExtTcsReqOff.PokeBRKR_e_ExtTcsReqOff
        Event_PokeBRKR_e_Not_OK_To_Race: start-on-event=PokeBRKR_e_Not_OK_To_Race, operation=PokeBRKR_e_Not_OK_To_Race.PokeBRKR_e_Not_OK_To_Race
        Event_PokeBRKR_e_OPDHoldStatus: start-on-event=PokeBRKR_e_OPDHoldStatus, operation=PokeBRKR_e_OPDHoldStatus.PokeBRKR_e_OPDHoldStatus
        Event_PokeBRKR_e_ReqSSC_IdlDst: start-on-event=PokeBRKR_e_ReqSSC_IdlDst, operation=PokeBRKR_e_ReqSSC_IdlDst.PokeBRKR_e_ReqSSC_IdlDst
        Event_PokeBRKR_e_ShiftInhibit: start-on-event=PokeBRKR_e_ShiftInhibit, operation=PokeBRKR_e_ShiftInhibit.PokeBRKR_e_ShiftInhibit
        Event_PokeBRKR_e_WhlSlpSt: start-on-event=PokeBRKR_e_WhlSlpSt, operation=PokeBRKR_e_WhlSlpSt.PokeBRKR_e_WhlSlpSt
        Event_PokeBRKR_l_BrkPedalTravel: start-on-event=PokeBRKR_l_BrkPedalTravel, operation=PokeBRKR_l_BrkPedalTravel.PokeBRKR_l_BrkPedalTravel
        Event_PokeBRKR_pbar_BrakePedalPressure: start-on-event=PokeBRKR_pbar_BrakePedalPressure, operation=PokeBRKR_pbar_BrakePedalPressure.PokeBRKR_pbar_BrakePedalPressure
      init event Event_BRKR_ac_Init: start-on-event=BRKR_ac_Init
      init event Event_PwrOn: start-on-event=BRKR_PwrOn
      explicit-inter-runnable-variables:
        36 x data, all with category=VALUE, sw-calibration-access=READ-ONLY:
          ImpndSkid_Init_IRV: type=Boolean, init-value=0
          VeBRKR_b_AeCoastReady_Init_IRV: type=Boolean, init-value=0
          VeBRKR_b_AeCoastReadyFA_Init_IRV: type=Boolean, init-value=0
          VeBRKR_e_AeCoastSwitchStat_Init_IRV: type=TeBRKR_e_AeCoastSwitchStat, init-value=CeBRKR_e_Button_Unpressed
          VeBRKR_b_AeCoastSwitchStatFA_Init_IRV: type=Boolean, init-value=0
          VeBRKR_e_AeCoastSwitch_Init_IRV: type=TeBRKR_e_AeCoastSwitchStat, init-value=CeBRKR_e_Button_Unpressed
          VeBRKR_b_AeCoastSwitchFA_Init_IRV: type=Boolean, init-value=0
          VeBRKR_e_AeCoastSwitchStatC1_Init_IRV: type=TeBRKR_e_AeCoastSwitchStat, init-value=CeBRKR_e_Button_Unpressed
          VeBRKR_b_AeCoastSwitchStatC1FA_Init_IRV: type=Boolean, init-value=0
          VeBRKR_e_AeCoastSwitchStatC2_Init_IRV: type=TeBRKR_e_AeCoastSwitchStat, init-value=CeBRKR_e_Button_Unpressed
          VeBRKR_b_AeCoastSwitchStatC2FA_Init_IRV: type=Boolean, init-value=0
          VeBRKR_b_EmsMlfAtv_Init_IRV: type=Boolean, init-value=0
          VeBRKR_b_EmsMlfAtvFA_Init_IRV: type=Boolean, init-value=0
          VeBRKR_b_HillHoldActive_Init_IRV: type=Boolean, init-value=0
          VeBRKR_b_HillHoldFailSts_Init_IRV: type=Boolean, init-value=0
          BrkPedalStat2_Init_IRV: type=TeBRKR_e_BrkPdl_Stat, init-value=CeBRKR_e_BrkNotApplied
          BrkPedalStat2FA_Init_IRV: type=Boolean, init-value=0
          BrkPedalSts_Init_IRV: type=TeBRKR_e_BrkPdl_Stat, init-value=CeBRKR_e_BrkNotApplied
          BrkPedalStsFA_Init_IRV: type=Boolean, init-value=0
          VeBRKR_b_ABSActive_write_Init_IRV: type=Boolean, init-value=0
          VeBRKR_b_ABSActiveFA_write_Init_IRV: type=Boolean, init-value=0
          BrkPedalDscrtInptFA_Init_IRV: type=Boolean, init-value=0
          BrkPedalDscrtInpt_Init_IRV: type=TeBRKR_e_BrkPdl_Stat, init-value=CeBRKR_e_BrkNotApplied
          VeBRKR_U_Brake_NO_Init_IRV: type=Float, init-value=0
          VeBRKR_Pct_BrkTravelSts_write_Init_IRV: type=Float, init-value=0
          VeBRKR_b_BrkTravelStsFA_write_Init_IRV: type=Boolean, init-value=0
          VeBRKR_b_Brake_NOFA_Init_IRV: type=Boolean, init-value=0
          VeBRKR_Pct_BrkTravelSt_C2CAN_Init_IRV: type=Float, init-value=0
          VeBRKR_b_BrkTravelSts_C2CANFA_Init_IRV: type=Boolean, init-value=0
          VeBRKR_b_BrkTravelSt_C2CANSgnl_Rcvd_Init_IRV: type=Boolean, init-value=0
          VeBRKR_b_Brake_NOSgnl_Rcvd_Init_IRV: type=Boolean, init-value=0
          VeBRKR_e_BrkPedalStat2_C2CAN_Init_IRV: type=TeBRKR_e_BrkPdl_Stat, init-value=CeBRKR_e_BrkNotApplied
          VeBRKR_b_BrkPedalStat2_C2CANFA_Init_IRV: type=Boolean, init-value=0
          VeBRKR_b_BrkPedalStat2_C2CANSgnl_Rcvd_Init_IRV: type=Boolean, init-value=0
          VeBRKR_b_HillHoldActiveFA_write_Init_IRV: type=Boolean, init-value=0
          VeBRKR_b_HillHoldFailStsFA_write_Init_IRV: type=Boolean, init-value=0
      79 x runnable:
        BRKR_ac_Init
          data-send-points:
            19 x access:
              OUT_VeBRKR_e_WhlSlpSt_Value: accessed-variable=VeBRKR_e_WhlSlpSt.Value
              OUT_VeBRKR_e_BrkPedalStat2_Value: accessed-variable=VeBRKR_e_BrkPedalStat2.Value
              OUT_VeBRKR_e_BrkPedalDscrtInpt_Value: accessed-variable=VeBRKR_e_BrkPedalDscrtInpt.Value
              OUT_VeBRKR_e_ShiftInhibit_Value: accessed-variable=VeBRKR_e_ShiftInhibit.Value
              OUT_VeBRKR_e_AHH_Ready_Status_Value: accessed-variable=VeBRKR_e_AHH_Ready_Status.Value
              OUT_VeBRKR_e_AeCoastSwitchStat_Value: accessed-variable=VeBRKR_e_AeCoastSwitchStat.Value
              OUT_VeBRKR_e_ComFailBSM_C1CAN_Value: accessed-variable=VeBRKR_e_ComFailBSM_C1CAN.Value
              OUT_VeBRKR_e_ComFailBSM_C2CAN_Value: accessed-variable=VeBRKR_e_ComFailBSM_C2CAN.Value
              OUT_VeBRKR_e_AeCoastSwitchStatC1_Value: accessed-variable=VeBRKR_e_AeCoastSwitchStatC1.Value
              OUT_VeBRKR_e_AeCoastSwitchStatC2_Value: accessed-variable=VeBRKR_e_AeCoastSwitchStatC2.Value
              OUT_VeBRKR_e_AeCoastSwitch_Value: accessed-variable=VeBRKR_e_AeCoastSwitch.Value
              OUT_VeBRKR_e_OPDHoldStatus_Value: accessed-variable=VeBRKR_e_OPDHoldStatus.Value
              OUT_VeBRKR_e_BrakeSrc_Value: accessed-variable=VeBRKR_e_BrakeSrc.Value
              OUT_VeBRKR_e_ExtBrkReqOff_Value: accessed-variable=VeBRKR_e_ExtBrkReqOff.Value
              OUT_VeBRKR_e_ExtTcsReqOff_Value: accessed-variable=VeBRKR_e_ExtTcsReqOff.Value
              OUT_VeBRKR_e_FaultSts_RgnCntrlSwCktHi_Value: accessed-variable=VeBRKR_e_FaultSts_RgnCntrlSwCktHi.Value
              OUT_VeBRKR_e_FaultSts_RgnCntrlSwCktLo_Value: accessed-variable=VeBRKR_e_FaultSts_RgnCntrlSwCktLo.Value
              OUT_VeBRKR_e_FaultSts_RgnCntrlSwCkt_Value: accessed-variable=VeBRKR_e_FaultSts_RgnCntrlSwCkt.Value
              OUT_VeBRKR_e_Not_OK_To_Race_Value: accessed-variable=VeBRKR_e_Not_OK_To_Race.Value
        BRKR_PwrOn
          data-send-points:
            84 x access:
              OUT_VeBRKR_b_ABSActive_Value: accessed-variable=VeBRKR_b_ABSActive.Value
              OUT_VeBRKR_P_BrkPrss_Value: accessed-variable=VeBRKR_P_BrkPrss.Value
              OUT_VeBRKR_b_BrkPrssFA_Value: accessed-variable=VeBRKR_b_BrkPrssFA.Value
              OUT_VeBRKR_e_AHH_Ready_Status_Value: accessed-variable=VeBRKR_e_AHH_Ready_Status.Value
              OUT_VeBRKR_b_AHH_Ready_StatusFA_Value: accessed-variable=VeBRKR_b_AHH_Ready_StatusFA.Value
              OUT_VeBRKR_b_MSRActive_FA_Value: accessed-variable=VeBRKR_b_MSRActive_FA.Value
              OUT_VeBRKR_e_ShiftInhibit_Value: accessed-variable=VeBRKR_e_ShiftInhibit.Value
              OUT_VeBRKR_b_MSRActive_Value: accessed-variable=VeBRKR_b_MSRActive.Value
              OUT_VeBRKR_b_ASRActive_FA_Value: accessed-variable=VeBRKR_b_ASRActive_FA.Value
              OUT_VeBRKR_b_ESCActiveFA_Value: accessed-variable=VeBRKR_b_ESCActiveFA.Value
              OUT_VeBRKR_b_ESCActive_Value: accessed-variable=VeBRKR_b_ESCActive.Value
              OUT_VeBRKR_e_WhlSlpSt_Value: accessed-variable=VeBRKR_e_WhlSlpSt.Value
              OUT_VeBRKR_b_ComFailBSM_C1CANFA_Value: accessed-variable=VeBRKR_b_ComFailBSM_C1CANFA.Value
              OUT_VeBRKR_e_ComFailBSM_C1CAN_Value: accessed-variable=VeBRKR_e_ComFailBSM_C1CAN.Value
              OUT_VeBRKR_b_ComFailBSM_C2CANFA_Value: accessed-variable=VeBRKR_b_ComFailBSM_C2CANFA.Value
              OUT_VeBRKR_e_ComFailBSM_C2CAN_Value: accessed-variable=VeBRKR_e_ComFailBSM_C2CAN.Value
              OUT_VeBRKR_b_ABSFailSts_Value: accessed-variable=VeBRKR_b_ABSFailSts.Value
              OUT_VeBRKR_b_ESCFailSts_Value: accessed-variable=VeBRKR_b_ESCFailSts.Value
              OUT_VeBRKR_b_BrkTravelStsFA_Value: accessed-variable=VeBRKR_b_BrkTravelStsFA.Value
              OUT_VeBRKR_b_ASRActive_Value: accessed-variable=VeBRKR_b_ASRActive.Value
              OUT_VeBRKR_Pct_BrkTravelSts_Value: accessed-variable=VeBRKR_Pct_BrkTravelSts.Value
              OUT_VeBRKR_b_HillHoldActiveFA_Value: accessed-variable=VeBRKR_b_HillHoldActiveFA.Value
              OUT_VeBRKR_b_HillHoldFailStsFA_Value: accessed-variable=VeBRKR_b_HillHoldFailStsFA.Value
              OUT_VeBRKR_e_OPDHoldStatus_Value: accessed-variable=VeBRKR_e_OPDHoldStatus.Value
              OUT_VeBRKR_b_OPDHoldStatusFA_Value: accessed-variable=VeBRKR_b_OPDHoldStatusFA.Value
              OUT_VeBRKR_b_CMMIntervention_Value: accessed-variable=VeBRKR_b_CMMIntervention.Value
              OUT_VeBRKR_l_BrkPedalTravel_Value: accessed-variable=VeBRKR_l_BrkPedalTravel.Value
              OUT_VeBRKR_b_FunctionSts_Value: accessed-variable=VeBRKR_b_FunctionSts.Value
              OUT_VeBRKR_b_BrkMaxTrqIntrvntn_Value: accessed-variable=VeBRKR_b_BrkMaxTrqIntrvntn.Value
              OUT_VeBRKR_b_BrkMaxTrqIntrvntnFA_Value: accessed-variable=VeBRKR_b_BrkMaxTrqIntrvntnFA.Value
              OUT_VeBRKR_b_BrkMinTrqIntrvntn_Value: accessed-variable=VeBRKR_b_BrkMinTrqIntrvntn.Value
              OUT_VeBRKR_b_BrkMinTrqIntrvntnFA_Value: accessed-variable=VeBRKR_b_BrkMinTrqIntrvntnFA.Value
              OUT_VeBRKR_b_ReqSSC_IdlDst_Value: accessed-variable=VeBRKR_b_ReqSSC_IdlDst.Value
              OUT_VeBRKR_b_BrkPdlFlt_Value: accessed-variable=VeBRKR_b_BrkPdlFlt.Value
              OUT_VeBRKR_b_BrkPedalTravelFA_Value: accessed-variable=VeBRKR_b_BrkPedalTravelFA.Value
              OUT_VeBRKR_b_BrkPdlFltFA_Value: accessed-variable=VeBRKR_b_BrkPdlFltFA.Value
              OUT_VeBRKR_e_ExtBrkReqOff_Value: accessed-variable=VeBRKR_e_ExtBrkReqOff.Value
              OUT_VeBRKR_b_ExtBrkReqOffFA_Value: accessed-variable=VeBRKR_b_ExtBrkReqOffFA.Value
              OUT_VeBRKR_e_ExtTcsReqOff_Value: accessed-variable=VeBRKR_e_ExtTcsReqOff.Value
              OUT_VeBRKR_b_ESCFailStsFA_Value: accessed-variable=VeBRKR_b_ESCFailStsFA.Value
              OUT_VeBRKR_b_ESCIntervention_Value: accessed-variable=VeBRKR_b_ESCIntervention.Value
              OUT_VeBRKR_pbar_BrakePedalPressure_Value: accessed-variable=VeBRKR_pbar_BrakePedalPressure.Value
              OUT_VeBRKR_b_ABSActiveFA_Value: accessed-variable=VeBRKR_b_ABSActiveFA.Value
              OUT_VeBRKR_e_BrkPedalStat2_Value: accessed-variable=VeBRKR_e_BrkPedalStat2.Value
              OUT_VeBRKR_b_BrkPedalStat2FA_Value: accessed-variable=VeBRKR_b_BrkPedalStat2FA.Value
              OUT_VeBRKR_e_BrkPedalDscrtInpt_Value: accessed-variable=VeBRKR_e_BrkPedalDscrtInpt.Value
              OUT_VeBRKR_b_BrkPedalDscrtInptFA_Value: accessed-variable=VeBRKR_b_BrkPedalDscrtInptFA.Value
              OUT_VeBRKR_b_ImpndSkid_Value: accessed-variable=VeBRKR_b_ImpndSkid.Value
              OUT_VeBRKR_e_AeCoastSwitchStat_Value: accessed-variable=VeBRKR_e_AeCoastSwitchStat.Value
              OUT_VeBRKR_b_AeCoastSwitchStatFA_Value: accessed-variable=VeBRKR_b_AeCoastSwitchStatFA.Value
              OUT_VeBRKR_b_AeCoastReady_Value: accessed-variable=VeBRKR_b_AeCoastReady.Value
              OUT_VeBRKR_b_AeCoastReadyFA_Value: accessed-variable=VeBRKR_b_AeCoastReadyFA.Value
              OUT_VeBRKR_b_AeCoastSwitchStatC1FA_Value: accessed-variable=VeBRKR_b_AeCoastSwitchStatC1FA.Value
              OUT_VeBRKR_b_AeCoastSwitchStatC2FA_Value: accessed-variable=VeBRKR_b_AeCoastSwitchStatC2FA.Value
              OUT_VeBRKR_b_EmsMlfAtv_Value: accessed-variable=VeBRKR_b_EmsMlfAtv.Value
              OUT_VeBRKR_b_EmsMlfAtvFA_Value: accessed-variable=VeBRKR_b_EmsMlfAtvFA.Value
              OUT_VeBRKR_b_AeCoastBtnCircuitLow_Value: accessed-variable=VeBRKR_b_AeCoastBtnCircuitLow.Value
              OUT_VeBRKR_b_AeCoastBtnCircuitHi_Value: accessed-variable=VeBRKR_b_AeCoastBtnCircuitHi.Value
              OUT_VeBRKR_e_AeCoastSwitchStatC1_Value: accessed-variable=VeBRKR_e_AeCoastSwitchStatC1.Value
              OUT_VeBRKR_e_AeCoastSwitchStatC2_Value: accessed-variable=VeBRKR_e_AeCoastSwitchStatC2.Value
              OUT_VeBRKR_b_AeCoastBtnDiagFail_Value: accessed-variable=VeBRKR_b_AeCoastBtnDiagFail.Value
              OUT_VeBRKR_b_HillHoldActive_Value: accessed-variable=VeBRKR_b_HillHoldActive.Value
              OUT_VeBRKR_b_HillHoldFailSts_Value: accessed-variable=VeBRKR_b_HillHoldFailSts.Value
              OUT_VeBRKR_e_AeCoastSwitch_Value: accessed-variable=VeBRKR_e_AeCoastSwitch.Value
              OUT_VeBRKR_b_AeCoastSwitchFA_Value: accessed-variable=VeBRKR_b_AeCoastSwitchFA.Value
              OUT_VeBRKR_e_BrakeSrc_Value: accessed-variable=VeBRKR_e_BrakeSrc.Value
              OUT_VeBRKR_b_ShortToGround_Value: accessed-variable=VeBRKR_b_ShortToGround.Value
              OUT_VeBRKR_b_ShortToPower_Value: accessed-variable=VeBRKR_b_ShortToPower.Value
              OUT_VeBRKR_b_ShortToOpen_Value: accessed-variable=VeBRKR_b_ShortToOpen.Value
              OUT_VeBRKR_b_AeCoastBtnCircuitLowC1_Value: accessed-variable=VeBRKR_b_AeCoastBtnCircuitLowC1.Value
              OUT_VeBRKR_b_AeCoastBtnCircuitLowC2_Value: accessed-variable=VeBRKR_b_AeCoastBtnCircuitLowC2.Value
              OUT_VeBRKR_b_AeCoastBtnCircuitHiC1_Value: accessed-variable=VeBRKR_b_AeCoastBtnCircuitHiC1.Value
              OUT_VeBRKR_b_AeCoastBtnCircuitHiC2_Value: accessed-variable=VeBRKR_b_AeCoastBtnCircuitHiC2.Value
              OUT_VeBRKR_e_FaultSts_RgnCntrlSwCktHi_Value: accessed-variable=VeBRKR_e_FaultSts_RgnCntrlSwCktHi.Value
              OUT_VeBRKR_e_FaultSts_RgnCntrlSwCktLo_Value: accessed-variable=VeBRKR_e_FaultSts_RgnCntrlSwCktLo.Value
              OUT_VeBRKR_e_FaultSts_RgnCntrlSwCkt_Value: accessed-variable=VeBRKR_e_FaultSts_RgnCntrlSwCkt.Value
              OUT_VeBRKR_b_VehicleStandStillSts_Value: accessed-variable=VeBRKR_b_VehicleStandStillSts.Value
              OUT_VeBRKR_b_VehicleStandStillStsFA_Value: accessed-variable=VeBRKR_b_VehicleStandStillStsFA.Value
              OUT_VeBRKR_e_Not_OK_To_Race_Value: accessed-variable=VeBRKR_e_Not_OK_To_Race.Value
              OUT_VeBRKR_b_Not_OK_To_RaceFA_Value: accessed-variable=VeBRKR_b_Not_OK_To_RaceFA.Value
              OUT_VeBRKR_b_BrkTempSts_Value: accessed-variable=VeBRKR_b_BrkTempSts.Value
              OUT_VeBRKR_b_BrkTempStsFA_Value: accessed-variable=VeBRKR_b_BrkTempStsFA.Value
              OUT_VeBRKR_Pct_OneBrkBoxPdlPosn_Value: accessed-variable=VeBRKR_Pct_OneBrkBoxPdlPosn.Value
              OUT_VeBRKR_b_OneBrkBoxPdlPosnFA_Value: accessed-variable=VeBRKR_b_OneBrkBoxPdlPosnFA.Value
          written-local-variables:
            36 x access:
              WV_BrkPedalDscrtInptFA_Init_IRV: accessed-variable=BrkPedalDscrtInptFA_Init_IRV
              WV_BrkPedalDscrtInpt_Init_IRV: accessed-variable=BrkPedalDscrtInpt_Init_IRV
              WV_BrkPedalStat2FA_Init_IRV: accessed-variable=BrkPedalStat2FA_Init_IRV
              WV_BrkPedalStat2_Init_IRV: accessed-variable=BrkPedalStat2_Init_IRV
              WV_BrkPedalStsFA_Init_IRV: accessed-variable=BrkPedalStsFA_Init_IRV
              WV_BrkPedalSts_Init_IRV: accessed-variable=BrkPedalSts_Init_IRV
              WV_ImpndSkid_Init_IRV: accessed-variable=ImpndSkid_Init_IRV
              WV_VeBRKR_Pct_BrkTravelSt_C2CAN_Init_IRV: accessed-variable=VeBRKR_Pct_BrkTravelSt_C2CAN_Init_IRV
              WV_VeBRKR_Pct_BrkTravelSts_write_Init_IRV: accessed-variable=VeBRKR_Pct_BrkTravelSts_write_Init_IRV
              WV_VeBRKR_U_Brake_NO_Init_IRV: accessed-variable=VeBRKR_U_Brake_NO_Init_IRV
              WV_VeBRKR_b_ABSActiveFA_write_Init_IRV: accessed-variable=VeBRKR_b_ABSActiveFA_write_Init_IRV
              WV_VeBRKR_b_ABSActive_write_Init_IRV: accessed-variable=VeBRKR_b_ABSActive_write_Init_IRV
              WV_VeBRKR_b_AeCoastReadyFA_Init_IRV: accessed-variable=VeBRKR_b_AeCoastReadyFA_Init_IRV
              WV_VeBRKR_b_AeCoastReady_Init_IRV: accessed-variable=VeBRKR_b_AeCoastReady_Init_IRV
              WV_VeBRKR_b_AeCoastSwitchFA_Init_IRV: accessed-variable=VeBRKR_b_AeCoastSwitchFA_Init_IRV
              WV_VeBRKR_b_AeCoastSwitchStatC1FA_Init_IRV: accessed-variable=VeBRKR_b_AeCoastSwitchStatC1FA_Init_IRV
              WV_VeBRKR_b_AeCoastSwitchStatC2FA_Init_IRV: accessed-variable=VeBRKR_b_AeCoastSwitchStatC2FA_Init_IRV
              WV_VeBRKR_b_AeCoastSwitchStatFA_Init_IRV: accessed-variable=VeBRKR_b_AeCoastSwitchStatFA_Init_IRV
              WV_VeBRKR_b_Brake_NOFA_Init_IRV: accessed-variable=VeBRKR_b_Brake_NOFA_Init_IRV
              WV_VeBRKR_b_Brake_NOSgnl_Rcvd_Init_IRV: accessed-variable=VeBRKR_b_Brake_NOSgnl_Rcvd_Init_IRV
              WV_VeBRKR_b_BrkPedalStat2_C2CANFA_Init_IRV: accessed-variable=VeBRKR_b_BrkPedalStat2_C2CANFA_Init_IRV
              WV_VeBRKR_b_BrkPedalStat2_C2CANSgnl_Rcvd_Init_IRV: accessed-variable=VeBRKR_b_BrkPedalStat2_C2CANSgnl_Rcvd_Init_IRV
              WV_VeBRKR_b_BrkTravelSt_C2CANSgnl_Rcvd_Init_IRV: accessed-variable=VeBRKR_b_BrkTravelSt_C2CANSgnl_Rcvd_Init_IRV
              WV_VeBRKR_b_BrkTravelStsFA_write_Init_IRV: accessed-variable=VeBRKR_b_BrkTravelStsFA_write_Init_IRV
              WV_VeBRKR_b_BrkTravelSts_C2CANFA_Init_IRV: accessed-variable=VeBRKR_b_BrkTravelSts_C2CANFA_Init_IRV
              WV_VeBRKR_b_EmsMlfAtvFA_Init_IRV: accessed-variable=VeBRKR_b_EmsMlfAtvFA_Init_IRV
              WV_VeBRKR_b_EmsMlfAtv_Init_IRV: accessed-variable=VeBRKR_b_EmsMlfAtv_Init_IRV
              WV_VeBRKR_b_HillHoldActiveFA_write_Init_IRV: accessed-variable=VeBRKR_b_HillHoldActiveFA_write_Init_IRV
              WV_VeBRKR_b_HillHoldActive_Init_IRV: accessed-variable=VeBRKR_b_HillHoldActive_Init_IRV
              WV_VeBRKR_b_HillHoldFailStsFA_write_Init_IRV: accessed-variable=VeBRKR_b_HillHoldFailStsFA_write_Init_IRV
              WV_VeBRKR_b_HillHoldFailSts_Init_IRV: accessed-variable=VeBRKR_b_HillHoldFailSts_Init_IRV
              WV_VeBRKR_e_AeCoastSwitchStatC1_Init_IRV: accessed-variable=VeBRKR_e_AeCoastSwitchStatC1_Init_IRV
              WV_VeBRKR_e_AeCoastSwitchStatC2_Init_IRV: accessed-variable=VeBRKR_e_AeCoastSwitchStatC2_Init_IRV
              WV_VeBRKR_e_AeCoastSwitchStat_Init_IRV: accessed-variable=VeBRKR_e_AeCoastSwitchStat_Init_IRV
              WV_VeBRKR_e_AeCoastSwitch_Init_IRV: accessed-variable=VeBRKR_e_AeCoastSwitch_Init_IRV
              WV_VeBRKR_e_BrkPedalStat2_C2CAN_Init_IRV: accessed-variable=VeBRKR_e_BrkPedalStat2_C2CAN_Init_IRV
        BRKR_MedTEB
          data-receive-point-by-arguments:
            8 x access:
              IN_VeBPSR_Pct_BrakePedalPct_Value: accessed-variable=VeBPSR_Pct_BrakePedalPct.Value
              IN_VeBPSR_b_BrkPdlSensorFail_Value: accessed-variable=VeBPSR_b_BrkPdlSensorFail.Value
              IN_VeBRKB_Pct_OneBrkBoxPdlPosn_Value: accessed-variable=VeBRKB_Pct_OneBrkBoxPdlPosn.Value
              IN_VeBRKB_b_BrkrSwitch_Value: accessed-variable=VeBRKB_b_BrkrSwitch.Value
              IN_VeBRKB_b_OneBrkBoxPdlPosnFA_Value: accessed-variable=VeBRKB_b_OneBrkBoxPdlPosnFA.Value
              IN_VeCSVR_v_VehSpd_Value: accessed-variable=VeCSVR_v_VehSpd.Value
              IN_VeDMAB_y_StatusByte_LostCommBCM_Value: accessed-variable=VeDMAB_y_StatusByte_LostCommBCM.Value
              IN_VePLTR_phi_EstSlopeAngle_Value: accessed-variable=VePLTR_phi_EstSlopeAngle.Value
          data-send-points:
            35 x access:
              OUT_VeBRKR_e_BrkPedalStat2_Value: accessed-variable=VeBRKR_e_BrkPedalStat2.Value
              OUT_VeBRKR_b_BrkPedalStat2FA_Value: accessed-variable=VeBRKR_b_BrkPedalStat2FA.Value
              OUT_VeBRKR_b_AeCoastSwitchStatFA_Value: accessed-variable=VeBRKR_b_AeCoastSwitchStatFA.Value
              OUT_VeBRKR_b_AeCoastReady_Value: accessed-variable=VeBRKR_b_AeCoastReady.Value
              OUT_VeBRKR_b_AeCoastReadyFA_Value: accessed-variable=VeBRKR_b_AeCoastReadyFA.Value
              OUT_VeBRKR_b_AeCoastSwitchStatC1FA_Value: accessed-variable=VeBRKR_b_AeCoastSwitchStatC1FA.Value
              OUT_VeBRKR_b_AeCoastSwitchStatC2FA_Value: accessed-variable=VeBRKR_b_AeCoastSwitchStatC2FA.Value
              OUT_VeBRKR_b_EmsMlfAtv_Value: accessed-variable=VeBRKR_b_EmsMlfAtv.Value
              OUT_VeBRKR_b_EmsMlfAtvFA_Value: accessed-variable=VeBRKR_b_EmsMlfAtvFA.Value
              OUT_VeBRKR_e_AeCoastSwitch_Value: accessed-variable=VeBRKR_e_AeCoastSwitch.Value
              OUT_VeBRKR_b_AeCoastSwitchFA_Value: accessed-variable=VeBRKR_b_AeCoastSwitchFA.Value
              OUT_VeBRKR_e_BrkPedalDscrtInpt_Value: accessed-variable=VeBRKR_e_BrkPedalDscrtInpt.Value
              OUT_VeBRKR_b_BrkPedalDscrtInptFA_Value: accessed-variable=VeBRKR_b_BrkPedalDscrtInptFA.Value
              OUT_VeBRKR_b_ImpndSkid_Value: accessed-variable=VeBRKR_b_ImpndSkid.Value
              OUT_VeBRKR_e_AeCoastSwitchStat_Value: accessed-variable=VeBRKR_e_AeCoastSwitchStat.Value
              OUT_VeBRKR_e_BrakeSrc_Value: accessed-variable=VeBRKR_e_BrakeSrc.Value
              OUT_VeBRKR_b_HillHoldActive_Value: accessed-variable=VeBRKR_b_HillHoldActive.Value
              OUT_VeBRKR_b_HillHoldFailSts_Value: accessed-variable=VeBRKR_b_HillHoldFailSts.Value
              OUT_VeBRKR_b_AeCoastBtnCircuitLow_Value: accessed-variable=VeBRKR_b_AeCoastBtnCircuitLow.Value
              OUT_VeBRKR_b_AeCoastBtnCircuitHi_Value: accessed-variable=VeBRKR_b_AeCoastBtnCircuitHi.Value
              OUT_VeBRKR_b_AeCoastBtnDiagFail_Value: accessed-variable=VeBRKR_b_AeCoastBtnDiagFail.Value
              OUT_VeBRKR_b_ShortToGround_Value: accessed-variable=VeBRKR_b_ShortToGround.Value
              OUT_VeBRKR_b_ShortToPower_Value: accessed-variable=VeBRKR_b_ShortToPower.Value
              OUT_VeBRKR_b_ShortToOpen_Value: accessed-variable=VeBRKR_b_ShortToOpen.Value
              OUT_VeBRKR_b_AeCoastBtnCircuitLowC1_Value: accessed-variable=VeBRKR_b_AeCoastBtnCircuitLowC1.Value
              OUT_VeBRKR_b_AeCoastBtnCircuitLowC2_Value: accessed-variable=VeBRKR_b_AeCoastBtnCircuitLowC2.Value
              OUT_VeBRKR_b_AeCoastBtnCircuitHiC1_Value: accessed-variable=VeBRKR_b_AeCoastBtnCircuitHiC1.Value
              OUT_VeBRKR_b_AeCoastBtnCircuitHiC2_Value: accessed-variable=VeBRKR_b_AeCoastBtnCircuitHiC2.Value
              OUT_VeBRKR_e_AeCoastSwitchStatC1_Value: accessed-variable=VeBRKR_e_AeCoastSwitchStatC1.Value
              OUT_VeBRKR_e_AeCoastSwitchStatC2_Value: accessed-variable=VeBRKR_e_AeCoastSwitchStatC2.Value
              OUT_VeBRKR_e_FaultSts_RgnCntrlSwCktHi_Value: accessed-variable=VeBRKR_e_FaultSts_RgnCntrlSwCktHi.Value
              OUT_VeBRKR_e_FaultSts_RgnCntrlSwCktLo_Value: accessed-variable=VeBRKR_e_FaultSts_RgnCntrlSwCktLo.Value
              OUT_VeBRKR_e_FaultSts_RgnCntrlSwCkt_Value: accessed-variable=VeBRKR_e_FaultSts_RgnCntrlSwCkt.Value
              OUT_VeBRKR_Pct_OneBrkBoxPdlPosn_Value: accessed-variable=VeBRKR_Pct_OneBrkBoxPdlPosn.Value
              OUT_VeBRKR_b_OneBrkBoxPdlPosnFA_Value: accessed-variable=VeBRKR_b_OneBrkBoxPdlPosnFA.Value
          read-local-variables:
            36 x access:
              RV_BrkPedalDscrtInptFA_Init_IRV: accessed-variable=BrkPedalDscrtInptFA_Init_IRV
              RV_BrkPedalDscrtInpt_Init_IRV: accessed-variable=BrkPedalDscrtInpt_Init_IRV
              RV_BrkPedalStat2FA_Init_IRV: accessed-variable=BrkPedalStat2FA_Init_IRV
              RV_BrkPedalStat2_Init_IRV: accessed-variable=BrkPedalStat2_Init_IRV
              RV_BrkPedalStsFA_Init_IRV: accessed-variable=BrkPedalStsFA_Init_IRV
              RV_BrkPedalSts_Init_IRV: accessed-variable=BrkPedalSts_Init_IRV
              RV_ImpndSkid_Init_IRV: accessed-variable=ImpndSkid_Init_IRV
              RV_VeBRKR_Pct_BrkTravelSt_C2CAN_Init_IRV: accessed-variable=VeBRKR_Pct_BrkTravelSt_C2CAN_Init_IRV
              RV_VeBRKR_Pct_BrkTravelSts_write_Init_IRV: accessed-variable=VeBRKR_Pct_BrkTravelSts_write_Init_IRV
              RV_VeBRKR_U_Brake_NO_Init_IRV: accessed-variable=VeBRKR_U_Brake_NO_Init_IRV
              RV_VeBRKR_b_ABSActiveFA_write_Init_IRV: accessed-variable=VeBRKR_b_ABSActiveFA_write_Init_IRV
              RV_VeBRKR_b_ABSActive_write_Init_IRV: accessed-variable=VeBRKR_b_ABSActive_write_Init_IRV
              RV_VeBRKR_b_AeCoastReadyFA_Init_IRV: accessed-variable=VeBRKR_b_AeCoastReadyFA_Init_IRV
              RV_VeBRKR_b_AeCoastReady_Init_IRV: accessed-variable=VeBRKR_b_AeCoastReady_Init_IRV
              RV_VeBRKR_b_AeCoastSwitchFA_Init_IRV: accessed-variable=VeBRKR_b_AeCoastSwitchFA_Init_IRV
              RV_VeBRKR_b_AeCoastSwitchStatC1FA_Init_IRV: accessed-variable=VeBRKR_b_AeCoastSwitchStatC1FA_Init_IRV
              RV_VeBRKR_b_AeCoastSwitchStatC2FA_Init_IRV: accessed-variable=VeBRKR_b_AeCoastSwitchStatC2FA_Init_IRV
              RV_VeBRKR_b_AeCoastSwitchStatFA_Init_IRV: accessed-variable=VeBRKR_b_AeCoastSwitchStatFA_Init_IRV
              RV_VeBRKR_b_Brake_NOFA_Init_IRV: accessed-variable=VeBRKR_b_Brake_NOFA_Init_IRV
              RV_VeBRKR_b_Brake_NOSgnl_Rcvd_Init_IRV: accessed-variable=VeBRKR_b_Brake_NOSgnl_Rcvd_Init_IRV
              RV_VeBRKR_b_BrkPedalStat2_C2CANFA_Init_IRV: accessed-variable=VeBRKR_b_BrkPedalStat2_C2CANFA_Init_IRV
              RV_VeBRKR_b_BrkPedalStat2_C2CANSgnl_Rcvd_Init_IRV: accessed-variable=VeBRKR_b_BrkPedalStat2_C2CANSgnl_Rcvd_Init_IRV
              RV_VeBRKR_b_BrkTravelSt_C2CANSgnl_Rcvd_Init_IRV: accessed-variable=VeBRKR_b_BrkTravelSt_C2CANSgnl_Rcvd_Init_IRV
              RV_VeBRKR_b_BrkTravelStsFA_write_Init_IRV: accessed-variable=VeBRKR_b_BrkTravelStsFA_write_Init_IRV
              RV_VeBRKR_b_BrkTravelSts_C2CANFA_Init_IRV: accessed-variable=VeBRKR_b_BrkTravelSts_C2CANFA_Init_IRV
              RV_VeBRKR_b_EmsMlfAtvFA_Init_IRV: accessed-variable=VeBRKR_b_EmsMlfAtvFA_Init_IRV
              RV_VeBRKR_b_EmsMlfAtv_Init_IRV: accessed-variable=VeBRKR_b_EmsMlfAtv_Init_IRV
              RV_VeBRKR_b_HillHoldActiveFA_write_Init_IRV: accessed-variable=VeBRKR_b_HillHoldActiveFA_write_Init_IRV
              RV_VeBRKR_b_HillHoldActive_Init_IRV: accessed-variable=VeBRKR_b_HillHoldActive_Init_IRV
              RV_VeBRKR_b_HillHoldFailStsFA_write_Init_IRV: accessed-variable=VeBRKR_b_HillHoldFailStsFA_write_Init_IRV
              RV_VeBRKR_b_HillHoldFailSts_Init_IRV: accessed-variable=VeBRKR_b_HillHoldFailSts_Init_IRV
              RV_VeBRKR_e_AeCoastSwitchStatC1_Init_IRV: accessed-variable=VeBRKR_e_AeCoastSwitchStatC1_Init_IRV
              RV_VeBRKR_e_AeCoastSwitchStatC2_Init_IRV: accessed-variable=VeBRKR_e_AeCoastSwitchStatC2_Init_IRV
              RV_VeBRKR_e_AeCoastSwitchStat_Init_IRV: accessed-variable=VeBRKR_e_AeCoastSwitchStat_Init_IRV
              RV_VeBRKR_e_AeCoastSwitch_Init_IRV: accessed-variable=VeBRKR_e_AeCoastSwitch_Init_IRV
              RV_VeBRKR_e_BrkPedalStat2_C2CAN_Init_IRV: accessed-variable=VeBRKR_e_BrkPedalStat2_C2CAN_Init_IRV
        FsftBRKR_P_BrkPrss
          data-send-points:
            access OUT_VeBRKR_b_BrkPrssFA_Value: accessed-variable=VeBRKR_b_BrkPrssFA.Value
        FsftBRKR_b_ABSActive
          data-send-points:
            access OUT_VeBRKR_b_ABSActiveFA_Value: accessed-variable=VeBRKR_b_ABSActiveFA.Value
          written-local-variables:
            access WV_VeBRKR_b_ABSActiveFA_write_Init_IRV: accessed-variable=VeBRKR_b_ABSActiveFA_write_Init_IRV
        FsftBRKR_b_ASRActive
          data-send-points:
            access OUT_VeBRKR_b_ASRActive_FA_Value: accessed-variable=VeBRKR_b_ASRActive_FA.Value
        FsftBRKR_b_AeCoastReady
          written-local-variables:
            access WV_VeBRKR_b_AeCoastReadyFA_Init_IRV: accessed-variable=VeBRKR_b_AeCoastReadyFA_Init_IRV
        FsftBRKR_b_BrkMaxTrqIntrvntn
          data-send-points:
            access OUT_VeBRKR_b_BrkMaxTrqIntrvntn_Value: accessed-variable=VeBRKR_b_BrkMaxTrqIntrvntn.Value
            access OUT_VeBRKR_b_BrkMaxTrqIntrvntnFA_Value: accessed-variable=VeBRKR_b_BrkMaxTrqIntrvntnFA.Value
        FsftBRKR_b_BrkMinTrqIntrvntn
          data-send-points:
            access OUT_VeBRKR_b_BrkMinTrqIntrvntn_Value: accessed-variable=VeBRKR_b_BrkMinTrqIntrvntn.Value
            access OUT_VeBRKR_b_BrkMinTrqIntrvntnFA_Value: accessed-variable=VeBRKR_b_BrkMinTrqIntrvntnFA.Value
        FsftBRKR_b_BrkPdlFlt
          data-send-points:
            access OUT_VeBRKR_b_BrkPdlFltFA_Value: accessed-variable=VeBRKR_b_BrkPdlFltFA.Value
        FsftBRKR_b_BrkPedalDscrtInpt
          written-local-variables:
            access WV_BrkPedalDscrtInptFA_Init_IRV: accessed-variable=BrkPedalDscrtInptFA_Init_IRV
        FsftBRKR_b_BrkPedalStat2
          written-local-variables:
            access WV_BrkPedalStat2FA_Init_IRV: accessed-variable=BrkPedalStat2FA_Init_IRV
        FsftBRKR_b_BrkPedalStat2_C2CAN
          written-local-variables:
            access WV_VeBRKR_b_BrkPedalStat2_C2CANFA_Init_IRV: accessed-variable=VeBRKR_b_BrkPedalStat2_C2CANFA_Init_IRV
        FsftBRKR_b_BrkPedalSts
          written-local-variables:
            access WV_BrkPedalStsFA_Init_IRV: accessed-variable=BrkPedalStsFA_Init_IRV
        FsftBRKR_b_BrkTmpSts
          data-send-points:
            access OUT_VeBRKR_b_BrkTempStsFA_Value: accessed-variable=VeBRKR_b_BrkTempStsFA.Value
        FsftBRKR_b_BrkTravelSts
          data-send-points:
            access OUT_VeBRKR_b_BrkTravelStsFA_Value: accessed-variable=VeBRKR_b_BrkTravelStsFA.Value
          written-local-variables:
            access WV_VeBRKR_b_BrkTravelStsFA_write_Init_IRV: accessed-variable=VeBRKR_b_BrkTravelStsFA_write_Init_IRV
        FsftBRKR_b_BrkTravelSts_C2CAN
          written-local-variables:
            access WV_VeBRKR_b_BrkTravelSts_C2CANFA_Init_IRV: accessed-variable=VeBRKR_b_BrkTravelSts_C2CANFA_Init_IRV
        FsftBRKR_b_ESCActive
          data-send-points:
            access OUT_VeBRKR_b_ESCActiveFA_Value: accessed-variable=VeBRKR_b_ESCActiveFA.Value
        FsftBRKR_b_ESCFailSts
          data-send-points:
            access OUT_VeBRKR_b_ESCFailStsFA_Value: accessed-variable=VeBRKR_b_ESCFailStsFA.Value
        FsftBRKR_b_ESCIntervention
        FsftBRKR_b_EmsMlfAtv
          written-local-variables:
            access WV_VeBRKR_b_EmsMlfAtvFA_Init_IRV: accessed-variable=VeBRKR_b_EmsMlfAtvFA_Init_IRV
        FsftBRKR_b_HillHoldActive
          data-send-points:
            access OUT_VeBRKR_b_HillHoldActiveFA_Value: accessed-variable=VeBRKR_b_HillHoldActiveFA.Value
          written-local-variables:
            access WV_VeBRKR_b_HillHoldActiveFA_write_Init_IRV: accessed-variable=VeBRKR_b_HillHoldActiveFA_write_Init_IRV
            access WV_VeBRKR_b_HillHoldActive_Init_IRV: accessed-variable=VeBRKR_b_HillHoldActive_Init_IRV
        FsftBRKR_b_HillHoldFailSts
          data-send-points:
            access OUT_VeBRKR_b_HillHoldFailStsFA_Value: accessed-variable=VeBRKR_b_HillHoldFailStsFA.Value
          written-local-variables:
            access WV_VeBRKR_b_HillHoldFailStsFA_write_Init_IRV: accessed-variable=VeBRKR_b_HillHoldFailStsFA_write_Init_IRV
            access WV_VeBRKR_b_HillHoldFailSts_Init_IRV: accessed-variable=VeBRKR_b_HillHoldFailSts_Init_IRV
        FsftBRKR_b_MSRActive
          data-send-points:
            access OUT_VeBRKR_b_MSRActive_FA_Value: accessed-variable=VeBRKR_b_MSRActive_FA.Value
        FsftBRKR_b_VehicleStandStillSts
          data-send-points:
            access OUT_VeBRKR_b_VehicleStandStillStsFA_Value: accessed-variable=VeBRKR_b_VehicleStandStillStsFA.Value
        FsftBRKR_e_AHH_Ready_Status
          data-send-points:
            access OUT_VeBRKR_e_AHH_Ready_Status_Value: accessed-variable=VeBRKR_e_AHH_Ready_Status.Value
            access OUT_VeBRKR_b_AHH_Ready_StatusFA_Value: accessed-variable=VeBRKR_b_AHH_Ready_StatusFA.Value
        FsftBRKR_e_AeCoastSwitch
          written-local-variables:
            access WV_VeBRKR_b_AeCoastSwitchFA_Init_IRV: accessed-variable=VeBRKR_b_AeCoastSwitchFA_Init_IRV
        FsftBRKR_e_AeCoastSwitchStat
          written-local-variables:
            access WV_VeBRKR_b_AeCoastSwitchStatFA_Init_IRV: accessed-variable=VeBRKR_b_AeCoastSwitchStatFA_Init_IRV
        FsftBRKR_e_AeCoastSwitchStatC1
          written-local-variables:
            access WV_VeBRKR_b_AeCoastSwitchStatC1FA_Init_IRV: accessed-variable=VeBRKR_b_AeCoastSwitchStatC1FA_Init_IRV
        FsftBRKR_e_AeCoastSwitchStatC2
          written-local-variables:
            access WV_VeBRKR_b_AeCoastSwitchStatC2FA_Init_IRV: accessed-variable=VeBRKR_b_AeCoastSwitchStatC2FA_Init_IRV
        FsftBRKR_e_BSMComFailDflt_C1CAN
          data-send-points:
            access OUT_VeBRKR_e_ComFailBSM_C1CAN_Value: accessed-variable=VeBRKR_e_ComFailBSM_C1CAN.Value
            access OUT_VeBRKR_b_ComFailBSM_C1CANFA_Value: accessed-variable=VeBRKR_b_ComFailBSM_C1CANFA.Value
        FsftBRKR_e_BSMComFailDflt_C2CAN
          data-send-points:
            access OUT_VeBRKR_e_ComFailBSM_C2CAN_Value: accessed-variable=VeBRKR_e_ComFailBSM_C2CAN.Value
            access OUT_VeBRKR_b_ComFailBSM_C2CANFA_Value: accessed-variable=VeBRKR_b_ComFailBSM_C2CANFA.Value
        FsftBRKR_e_ExtBrkReqOff
          data-send-points:
            access OUT_VeBRKR_b_ExtBrkReqOffFA_Value: accessed-variable=VeBRKR_b_ExtBrkReqOffFA.Value
        FsftBRKR_e_Not_OK_To_Race
          data-send-points:
            access OUT_VeBRKR_b_Not_OK_To_RaceFA_Value: accessed-variable=VeBRKR_b_Not_OK_To_RaceFA.Value
        FsftBRKR_e_OPDHoldStatus
          data-send-points:
            access OUT_VeBRKR_b_OPDHoldStatusFA_Value: accessed-variable=VeBRKR_b_OPDHoldStatusFA.Value
        FsftBRKR_pbar_BrakePedalPressure
        PokeBRKR_P_BrkPrss
          data-send-points:
            access OUT_VeBRKR_P_BrkPrss_Value: accessed-variable=VeBRKR_P_BrkPrss.Value
            access OUT_VeBRKR_b_BrkPrssFA_Value: accessed-variable=VeBRKR_b_BrkPrssFA.Value
        PokeBRKR_Pct_BrkTravelSt_C2CAN
          written-local-variables:
            access WV_VeBRKR_Pct_BrkTravelSt_C2CAN_Init_IRV: accessed-variable=VeBRKR_Pct_BrkTravelSt_C2CAN_Init_IRV
            access WV_VeBRKR_b_BrkTravelSts_C2CANFA_Init_IRV: accessed-variable=VeBRKR_b_BrkTravelSts_C2CANFA_Init_IRV
            access WV_VeBRKR_b_BrkTravelSt_C2CANSgnl_Rcvd_Init_IRV: accessed-variable=VeBRKR_b_BrkTravelSt_C2CANSgnl_Rcvd_Init_IRV
        PokeBRKR_Pct_BrkTravelSts
          data-send-points:
            access OUT_VeBRKR_Pct_BrkTravelSts_Value: accessed-variable=VeBRKR_Pct_BrkTravelSts.Value
            access OUT_VeBRKR_b_BrkTravelStsFA_Value: accessed-variable=VeBRKR_b_BrkTravelStsFA.Value
          written-local-variables:
            access WV_VeBRKR_Pct_BrkTravelSts_write_Init_IRV: accessed-variable=VeBRKR_Pct_BrkTravelSts_write_Init_IRV
            access WV_VeBRKR_b_BrkTravelStsFA_write_Init_IRV: accessed-variable=VeBRKR_b_BrkTravelStsFA_write_Init_IRV
        PokeBRKR_U_Brake_NO
          written-local-variables:
            access WV_VeBRKR_U_Brake_NO_Init_IRV: accessed-variable=VeBRKR_U_Brake_NO_Init_IRV
            access WV_VeBRKR_b_Brake_NOFA_Init_IRV: accessed-variable=VeBRKR_b_Brake_NOFA_Init_IRV
            access WV_VeBRKR_b_Brake_NOSgnl_Rcvd_Init_IRV: accessed-variable=VeBRKR_b_Brake_NOSgnl_Rcvd_Init_IRV
        PokeBRKR_b_ABSActive
          data-send-points:
            access OUT_VeBRKR_b_ABSActive_Value: accessed-variable=VeBRKR_b_ABSActive.Value
            access OUT_VeBRKR_b_ABSActiveFA_Value: accessed-variable=VeBRKR_b_ABSActiveFA.Value
          written-local-variables:
            access WV_VeBRKR_b_ABSActiveFA_write_Init_IRV: accessed-variable=VeBRKR_b_ABSActiveFA_write_Init_IRV
            access WV_VeBRKR_b_ABSActive_write_Init_IRV: accessed-variable=VeBRKR_b_ABSActive_write_Init_IRV
        PokeBRKR_b_ABSFailSts
          data-send-points:
            access OUT_VeBRKR_b_ABSFailSts_Value: accessed-variable=VeBRKR_b_ABSFailSts.Value
        PokeBRKR_b_ASRActive
          data-send-points:
            access OUT_VeBRKR_b_ASRActive_Value: accessed-variable=VeBRKR_b_ASRActive.Value
            access OUT_VeBRKR_b_ASRActive_FA_Value: accessed-variable=VeBRKR_b_ASRActive_FA.Value
        PokeBRKR_b_AeCoastReady
          written-local-variables:
            access WV_VeBRKR_b_AeCoastReadyFA_Init_IRV: accessed-variable=VeBRKR_b_AeCoastReadyFA_Init_IRV
            access WV_VeBRKR_b_AeCoastReady_Init_IRV: accessed-variable=VeBRKR_b_AeCoastReady_Init_IRV
        PokeBRKR_b_BrkMaxTrqIntrvntn
          data-send-points:
            access OUT_VeBRKR_b_BrkMaxTrqIntrvntn_Value: accessed-variable=VeBRKR_b_BrkMaxTrqIntrvntn.Value
            access OUT_VeBRKR_b_BrkMaxTrqIntrvntnFA_Value: accessed-variable=VeBRKR_b_BrkMaxTrqIntrvntnFA.Value
        PokeBRKR_b_BrkMinTrqIntrvntn
          data-send-points:
            access OUT_VeBRKR_b_BrkMinTrqIntrvntn_Value: accessed-variable=VeBRKR_b_BrkMinTrqIntrvntn.Value
            access OUT_VeBRKR_b_BrkMinTrqIntrvntnFA_Value: accessed-variable=VeBRKR_b_BrkMinTrqIntrvntnFA.Value
        PokeBRKR_b_BrkPdlFlt
          data-send-points:
            access OUT_VeBRKR_b_BrkPdlFlt_Value: accessed-variable=VeBRKR_b_BrkPdlFlt.Value
            access OUT_VeBRKR_b_BrkPdlFltFA_Value: accessed-variable=VeBRKR_b_BrkPdlFltFA.Value
        PokeBRKR_b_BrkTmpSts
          data-send-points:
            access OUT_VeBRKR_b_BrkTempSts_Value: accessed-variable=VeBRKR_b_BrkTempSts.Value
            access OUT_VeBRKR_b_BrkTempStsFA_Value: accessed-variable=VeBRKR_b_BrkTempStsFA.Value
        PokeBRKR_b_CMMIntervention
          data-send-points:
            access OUT_VeBRKR_b_CMMIntervention_Value: accessed-variable=VeBRKR_b_CMMIntervention.Value
        PokeBRKR_b_ESCActive
          data-send-points:
            access OUT_VeBRKR_b_ESCActive_Value: accessed-variable=VeBRKR_b_ESCActive.Value
            access OUT_VeBRKR_b_ESCActiveFA_Value: accessed-variable=VeBRKR_b_ESCActiveFA.Value
        PokeBRKR_b_ESCFailSts
          data-send-points:
            access OUT_VeBRKR_b_ESCFailSts_Value: accessed-variable=VeBRKR_b_ESCFailSts.Value
            access OUT_VeBRKR_b_ESCFailStsFA_Value: accessed-variable=VeBRKR_b_ESCFailStsFA.Value
        PokeBRKR_b_ESCIntervention
          data-send-points:
            access OUT_VeBRKR_b_ESCIntervention_Value: accessed-variable=VeBRKR_b_ESCIntervention.Value
        PokeBRKR_b_EmsMlfAtv
          written-local-variables:
            access WV_VeBRKR_b_EmsMlfAtvFA_Init_IRV: accessed-variable=VeBRKR_b_EmsMlfAtvFA_Init_IRV
            access WV_VeBRKR_b_EmsMlfAtv_Init_IRV: accessed-variable=VeBRKR_b_EmsMlfAtv_Init_IRV
        PokeBRKR_b_FunctionSts
          data-send-points:
            access OUT_VeBRKR_b_FunctionSts_Value: accessed-variable=VeBRKR_b_FunctionSts.Value
        PokeBRKR_b_HillHoldActive
          data-send-points:
            access OUT_VeBRKR_b_HillHoldActiveFA_Value: accessed-variable=VeBRKR_b_HillHoldActiveFA.Value
          written-local-variables:
            access WV_VeBRKR_b_HillHoldActiveFA_write_Init_IRV: accessed-variable=VeBRKR_b_HillHoldActiveFA_write_Init_IRV
            access WV_VeBRKR_b_HillHoldActive_Init_IRV: accessed-variable=VeBRKR_b_HillHoldActive_Init_IRV
        PokeBRKR_b_HillHoldFailSts
          data-send-points:
            access OUT_VeBRKR_b_HillHoldFailStsFA_Value: accessed-variable=VeBRKR_b_HillHoldFailStsFA.Value
          written-local-variables:
            access WV_VeBRKR_b_HillHoldFailStsFA_write_Init_IRV: accessed-variable=VeBRKR_b_HillHoldFailStsFA_write_Init_IRV
            access WV_VeBRKR_b_HillHoldFailSts_Init_IRV: accessed-variable=VeBRKR_b_HillHoldFailSts_Init_IRV
        PokeBRKR_b_ImpndSkid
          written-local-variables:
            access WV_ImpndSkid_Init_IRV: accessed-variable=ImpndSkid_Init_IRV
        PokeBRKR_b_MSRActive
          data-send-points:
            access OUT_VeBRKR_b_MSRActive_Value: accessed-variable=VeBRKR_b_MSRActive.Value
            access OUT_VeBRKR_b_MSRActive_FA_Value: accessed-variable=VeBRKR_b_MSRActive_FA.Value
        PokeBRKR_b_VehicleStandStillSts
          data-send-points:
            access OUT_VeBRKR_b_VehicleStandStillSts_Value: accessed-variable=VeBRKR_b_VehicleStandStillSts.Value
            access OUT_VeBRKR_b_VehicleStandStillStsFA_Value: accessed-variable=VeBRKR_b_VehicleStandStillStsFA.Value
        PokeBRKR_e_AHH_Ready_Status
          data-send-points:
            access OUT_VeBRKR_e_AHH_Ready_Status_Value: accessed-variable=VeBRKR_e_AHH_Ready_Status.Value
            access OUT_VeBRKR_b_AHH_Ready_StatusFA_Value: accessed-variable=VeBRKR_b_AHH_Ready_StatusFA.Value
        PokeBRKR_e_AeCoastSwitch
          written-local-variables:
            access WV_VeBRKR_b_AeCoastSwitchFA_Init_IRV: accessed-variable=VeBRKR_b_AeCoastSwitchFA_Init_IRV
            access WV_VeBRKR_e_AeCoastSwitch_Init_IRV: accessed-variable=VeBRKR_e_AeCoastSwitch_Init_IRV
        PokeBRKR_e_AeCoastSwitchStat
          written-local-variables:
            access WV_VeBRKR_b_AeCoastSwitchStatFA_Init_IRV: accessed-variable=VeBRKR_b_AeCoastSwitchStatFA_Init_IRV
            access WV_VeBRKR_e_AeCoastSwitchStat_Init_IRV: accessed-variable=VeBRKR_e_AeCoastSwitchStat_Init_IRV
        PokeBRKR_e_AeCoastSwitchStatC1
          written-local-variables:
            access WV_VeBRKR_b_AeCoastSwitchStatC1FA_Init_IRV: accessed-variable=VeBRKR_b_AeCoastSwitchStatC1FA_Init_IRV
            access WV_VeBRKR_e_AeCoastSwitchStatC1_Init_IRV: accessed-variable=VeBRKR_e_AeCoastSwitchStatC1_Init_IRV
        PokeBRKR_e_AeCoastSwitchStatC2
          written-local-variables:
            access WV_VeBRKR_b_AeCoastSwitchStatC2FA_Init_IRV: accessed-variable=VeBRKR_b_AeCoastSwitchStatC2FA_Init_IRV
            access WV_VeBRKR_e_AeCoastSwitchStatC2_Init_IRV: accessed-variable=VeBRKR_e_AeCoastSwitchStatC2_Init_IRV
        PokeBRKR_e_BSMComFail_C1CAN
          data-send-points:
            access OUT_VeBRKR_e_ComFailBSM_C1CAN_Value: accessed-variable=VeBRKR_e_ComFailBSM_C1CAN.Value
            access OUT_VeBRKR_b_ComFailBSM_C1CANFA_Value: accessed-variable=VeBRKR_b_ComFailBSM_C1CANFA.Value
        PokeBRKR_e_BSMComFail_C2CAN
          data-send-points:
            access OUT_VeBRKR_e_ComFailBSM_C2CAN_Value: accessed-variable=VeBRKR_e_ComFailBSM_C2CAN.Value
            access OUT_VeBRKR_b_ComFailBSM_C2CANFA_Value: accessed-variable=VeBRKR_b_ComFailBSM_C2CANFA.Value
        PokeBRKR_e_BrkPedalDscrtInpt
          written-local-variables:
            access WV_BrkPedalDscrtInptFA_Init_IRV: accessed-variable=BrkPedalDscrtInptFA_Init_IRV
            access WV_BrkPedalDscrtInpt_Init_IRV: accessed-variable=BrkPedalDscrtInpt_Init_IRV
        PokeBRKR_e_BrkPedalStat2
          written-local-variables:
            access WV_BrkPedalStat2FA_Init_IRV: accessed-variable=BrkPedalStat2FA_Init_IRV
            access WV_BrkPedalStat2_Init_IRV: accessed-variable=BrkPedalStat2_Init_IRV
        PokeBRKR_e_BrkPedalStat2_C2CAN
          written-local-variables:
            access WV_VeBRKR_b_BrkPedalStat2_C2CANFA_Init_IRV: accessed-variable=VeBRKR_b_BrkPedalStat2_C2CANFA_Init_IRV
            access WV_VeBRKR_b_BrkPedalStat2_C2CANSgnl_Rcvd_Init_IRV: accessed-variable=VeBRKR_b_BrkPedalStat2_C2CANSgnl_Rcvd_Init_IRV
            access WV_VeBRKR_e_BrkPedalStat2_C2CAN_Init_IRV: accessed-variable=VeBRKR_e_BrkPedalStat2_C2CAN_Init_IRV
        PokeBRKR_e_BrkPedalSts
          written-local-variables:
            access WV_BrkPedalStsFA_Init_IRV: accessed-variable=BrkPedalStsFA_Init_IRV
            access WV_BrkPedalSts_Init_IRV: accessed-variable=BrkPedalSts_Init_IRV
        PokeBRKR_e_ExtBrkReqOff
          data-send-points:
            access OUT_VeBRKR_e_ExtBrkReqOff_Value: accessed-variable=VeBRKR_e_ExtBrkReqOff.Value
            access OUT_VeBRKR_b_ExtBrkReqOffFA_Value: accessed-variable=VeBRKR_b_ExtBrkReqOffFA.Value
        PokeBRKR_e_ExtTcsReqOff
          data-send-points:
            access OUT_VeBRKR_e_ExtTcsReqOff_Value: accessed-variable=VeBRKR_e_ExtTcsReqOff.Value
        PokeBRKR_e_Not_OK_To_Race
          data-send-points:
            access OUT_VeBRKR_e_Not_OK_To_Race_Value: accessed-variable=VeBRKR_e_Not_OK_To_Race.Value
            access OUT_VeBRKR_b_Not_OK_To_RaceFA_Value: accessed-variable=VeBRKR_b_Not_OK_To_RaceFA.Value
        PokeBRKR_e_OPDHoldStatus
          data-send-points:
            access OUT_VeBRKR_e_OPDHoldStatus_Value: accessed-variable=VeBRKR_e_OPDHoldStatus.Value
            access OUT_VeBRKR_b_OPDHoldStatusFA_Value: accessed-variable=VeBRKR_b_OPDHoldStatusFA.Value
        PokeBRKR_e_ReqSSC_IdlDst
          data-send-points:
            access OUT_VeBRKR_b_ReqSSC_IdlDst_Value: accessed-variable=VeBRKR_b_ReqSSC_IdlDst.Value
        PokeBRKR_e_ShiftInhibit
          data-send-points:
            access OUT_VeBRKR_e_ShiftInhibit_Value: accessed-variable=VeBRKR_e_ShiftInhibit.Value
        PokeBRKR_e_WhlSlpSt
          data-send-points:
            access OUT_VeBRKR_e_WhlSlpSt_Value: accessed-variable=VeBRKR_e_WhlSlpSt.Value
        PokeBRKR_l_BrkPedalTravel
          data-send-points:
            access OUT_VeBRKR_l_BrkPedalTravel_Value: accessed-variable=VeBRKR_l_BrkPedalTravel.Value
            access OUT_VeBRKR_b_BrkPedalTravelFA_Value: accessed-variable=VeBRKR_b_BrkPedalTravelFA.Value
        PokeBRKR_pbar_BrakePedalPressure
          data-send-points:
            access OUT_VeBRKR_pbar_BrakePedalPressure_Value: accessed-variable=VeBRKR_pbar_BrakePedalPressure.Value
      variation point proxy Variant_BRKR_1: category=CONDITION, condition-access=0
